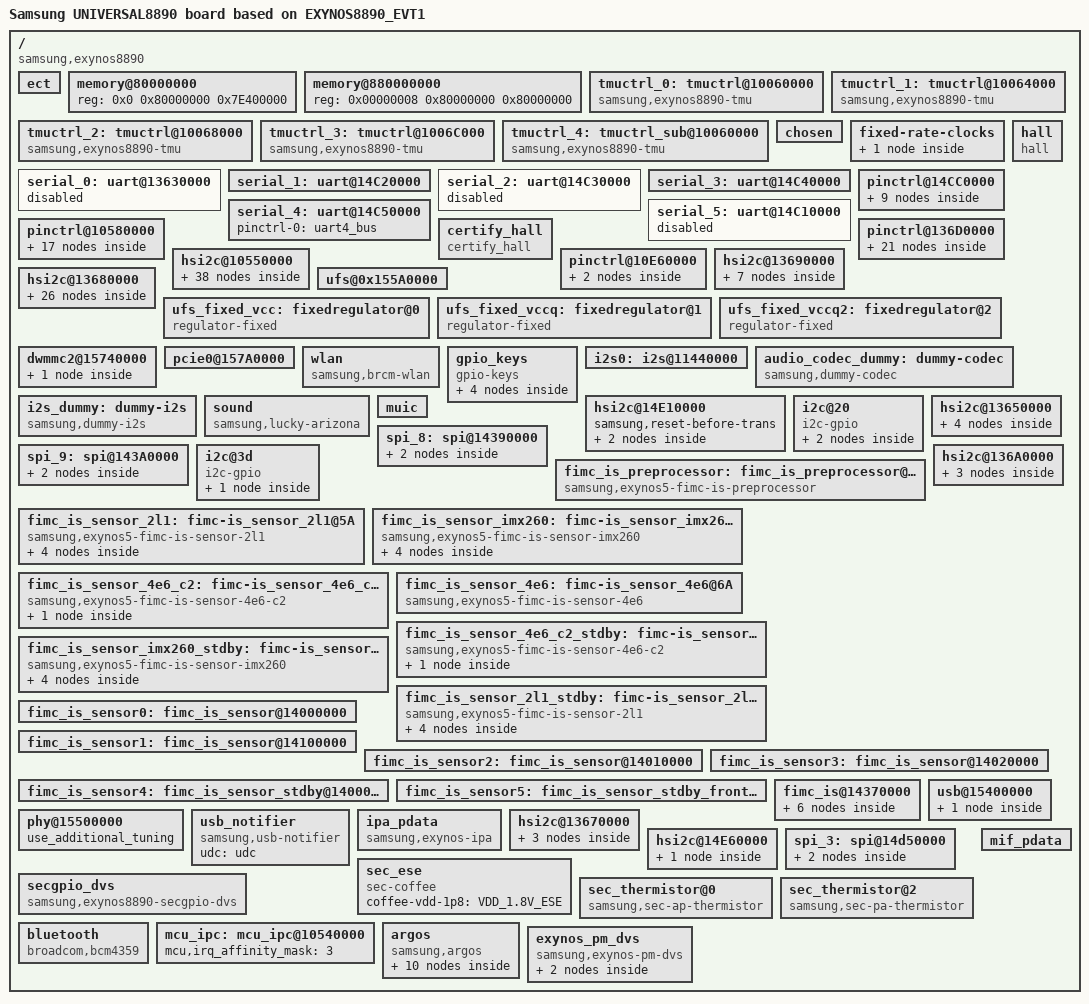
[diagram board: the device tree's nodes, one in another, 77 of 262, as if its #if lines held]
/*
 * SAMSUNG UNIVERSAL8890 board device tree source
 *
 * Copyright (c) 2013 Samsung Electronics Co., Ltd.
 *		http://www.samsung.com
 *
 * This program is free software; you can redistribute it and/or modify
 * it under the terms of the GNU General Public License version 2 as
 * published by the Free Software Foundation.
*/

#include "exynos8890.dtsi"
#include "exynos8890-rmem.dtsi"
#include "modem-ss335ap-pdata.dtsi"
#include "exynos8890-display-lcd.dtsi"

/ {
	model = "Samsung UNIVERSAL8890 board based on EXYNOS8890_EVT1";
	compatible = "samsung,exynos8890", "samsung,UNIVERSAL8890";

	ect {
		parameter_address = <0xA0000000>;
		parameter_size = <0x19000>;
	};

	memory@80000000 {
		device_type = "memory";
		reg = <0x0 0x80000000 0x7E400000>;
	};

	memory@880000000 {
		device_type = "memory";
		reg = <0x00000008 0x80000000 0x80000000>;
	};

	tmuctrl_0: tmuctrl@10060000 {
		compatible = "samsung,exynos8890-tmu";
		reg = <0x0 0x10060000 0x200>;
		interrupts = <0 77 0>;
		sensor_type = <NORMAL_SENSOR>;
		max_trigger_level = <8>;
		non_hw_trigger_levels = <7>;

		/* Throttling Level */
		trigger_levels_0 = <76>;
		trigger_levels_1 = <81>;
		trigger_levels_2 = <86>;
		trigger_levels_3 = <91>;
		trigger_levels_4 = <96>;
		trigger_levels_5 = <101>;
		trigger_levels_6 = <106>;
		trigger_levels_7 = <115>;

		trigger_enable_0 = <ENABLE>;
		trigger_enable_1 = <ENABLE>;
		trigger_enable_2 = <ENABLE>;
		trigger_enable_3 = <ENABLE>;
		trigger_enable_4 = <ENABLE>;
		trigger_enable_5 = <ENABLE>;
		trigger_enable_6 = <ENABLE>;
		trigger_enable_7 = <ENABLE>;

		trigger_type_0 = <THROTTLE_ACTIVE>;
		trigger_type_1 = <THROTTLE_ACTIVE>;
		trigger_type_2 = <THROTTLE_ACTIVE>;
		trigger_type_3 = <THROTTLE_ACTIVE>;
		trigger_type_4 = <THROTTLE_ACTIVE>;
		trigger_type_5 = <THROTTLE_ACTIVE>;
		trigger_type_6 = <THROTTLE_ACTIVE>;
		trigger_type_7 = <HW_TRIP>;

		freq_tab_count = <3>;

		freq_clip_max_0 = <1872000>;
		freq_clip_max_1 = <1352000>;
		freq_clip_max_2 = <728000>;

		cooling_level_0 = <76>;
		cooling_level_1 = <81>;
		cooling_level_2 = <86>;

		hotplug_enable = <1>;
		hotplug_in_threshold = <93>;
		hotplug_out_threshold = <96>;
	};

	tmuctrl_1: tmuctrl@10064000 {
		compatible = "samsung,exynos8890-tmu";
		reg = <0x0 0x10064000 0x200>;
		interrupts = <0 75 0>;
		sensor_type = <NORMAL_SENSOR>;
		max_trigger_level = <8>;
		non_hw_trigger_levels = <7>;

		/* Throttling Level */
		trigger_levels_0 = <76>;
		trigger_levels_1 = <81>;
		trigger_levels_2 = <86>;
		trigger_levels_3 = <91>;
		trigger_levels_4 = <96>;
		trigger_levels_5 = <101>;
		trigger_levels_6 = <106>;
		trigger_levels_7 = <115>;

		trigger_enable_0 = <ENABLE>;
		trigger_enable_1 = <ENABLE>;
		trigger_enable_2 = <ENABLE>;
		trigger_enable_3 = <ENABLE>;
		trigger_enable_4 = <ENABLE>;
		trigger_enable_5 = <ENABLE>;
		trigger_enable_6 = <ENABLE>;
		trigger_enable_7 = <ENABLE>;

		trigger_type_0 = <THROTTLE_ACTIVE>;
		trigger_type_1 = <THROTTLE_ACTIVE>;
		trigger_type_2 = <THROTTLE_ACTIVE>;
		trigger_type_3 = <THROTTLE_ACTIVE>;
		trigger_type_4 = <THROTTLE_ACTIVE>;
		trigger_type_5 = <THROTTLE_ACTIVE>;
		trigger_type_6 = <THROTTLE_ACTIVE>;
		trigger_type_7 = <HW_TRIP>;

		freq_tab_count = <5>;

		freq_clip_max_0 = <1482000>;
		freq_clip_max_1 = <1378000>;
		freq_clip_max_2 = <1170000>;
		freq_clip_max_3 = <1066000>;
		freq_clip_max_4 = <442000>;

		cooling_level_0 = <76>;
		cooling_level_1 = <81>;
		cooling_level_2 = <86>;
		cooling_level_3 = <91>;
		cooling_level_4 = <96>;
	};

	tmuctrl_2: tmuctrl@10068000 {
		compatible = "samsung,exynos8890-tmu";
		reg = <0x0 0x10068000 0x200>;
		interrupts = <0 78 0>;
		sensor_type = <NORMAL_SENSOR>;
		max_trigger_level = <8>;
		non_hw_trigger_levels = <7>;

		/* Throttling Level */
		trigger_levels_0 = <66>;
		trigger_levels_1 = <71>;
		trigger_levels_2 = <76>;
		trigger_levels_3 = <81>;
		trigger_levels_4 = <86>;
		trigger_levels_5 = <91>;
		trigger_levels_6 = <96>;
		trigger_levels_7 = <115>;

		trigger_enable_0 = <ENABLE>;
		trigger_enable_1 = <ENABLE>;
		trigger_enable_2 = <ENABLE>;
		trigger_enable_3 = <ENABLE>;
		trigger_enable_4 = <ENABLE>;
		trigger_enable_5 = <ENABLE>;
		trigger_enable_6 = <ENABLE>;
		trigger_enable_7 = <ENABLE>;

		trigger_type_0 = <THROTTLE_ACTIVE>;
		trigger_type_1 = <THROTTLE_ACTIVE>;
		trigger_type_2 = <THROTTLE_ACTIVE>;
		trigger_type_3 = <THROTTLE_ACTIVE>;
		trigger_type_4 = <THROTTLE_ACTIVE>;
		trigger_type_5 = <THROTTLE_ACTIVE>;
		trigger_type_6 = <THROTTLE_ACTIVE>;
		trigger_type_7 = <HW_TRIP>;

		freq_tab_count = <6>;

		freq_clip_max_0 = <600000>;
		freq_clip_max_1 = <600000>;
		freq_clip_max_2 = <546000>;
		freq_clip_max_3 = <419000>;
		freq_clip_max_4 = <260000>;
		freq_clip_max_5 = <260000>;

		cooling_level_0 = <76>;
		cooling_level_1 = <81>;
		cooling_level_2 = <86>;
		cooling_level_3 = <91>;
		cooling_level_4 = <96>;
		cooling_level_5 = <101>;

		/* gpu cooling related table */
		/* flags, driver_data(index), frequency */
		gpu_idx_num = <7>;
		gpu_cooling_table = < 0 0 650000
		                      0 1 600000
		                      0 2 546000
		                      0 3 419000
		                      0 4 338000
		                      0 5 260000
		                      0 6 TABLE_END>;
	};

	tmuctrl_3: tmuctrl@1006C000 {
		compatible = "samsung,exynos8890-tmu";
		reg = <0x0 0x1006C000 0x200>;
		interrupts = <0 76 0>;
		sensor_type = <NORMAL_SENSOR>;
		max_trigger_level = <4>;
		non_hw_trigger_levels = <4>;

		/* Throttling Level */
		trigger_levels_0 = <96>;
		trigger_levels_1 = <101>;
		trigger_levels_2 = <106>;
		trigger_levels_3 = <110>;

		trigger_enable_0 = <ENABLE>;
		trigger_enable_1 = <ENABLE>;
		trigger_enable_2 = <ENABLE>;
		trigger_enable_3 = <ENABLE>;

		trigger_type_0 = <THROTTLE_ACTIVE>;
		trigger_type_1 = <THROTTLE_ACTIVE>;
		trigger_type_2 = <THROTTLE_ACTIVE>;
		trigger_type_3 = <THROTTLE_ACTIVE>;

		freq_tab_count = <3>;

		freq_clip_max_0 = <60>;
		freq_clip_max_1 = <15>;
		freq_clip_max_2 = <5>;

		cooling_level_0 = <96>;
		cooling_level_1 = <101>;
		cooling_level_2 = <106>;

		/* isp cooling related table */
		/* flags, driver_data(index), frequency */
		isp_idx_num = <7>;
		isp_cooling_table = < 0 0 63
				      0 1 62
				      0 2 61
				      0 3 60
				      0 4 15
				      0 5  5
				      0 6 TABLE_END>;
	};

	tmuctrl_4: tmuctrl_sub@10060000 {
		compatible = "samsung,exynos8890-tmu";
		reg = <0x0 0x10060000 0x200>;
		interrupts = <0 77 0>;
		sensor_type = <VIRTUAL_SENSOR>;
		real_tmuctrl_id = <0>;
		max_trigger_level = <8>;
		non_hw_trigger_levels = <7>;

		/* Throttling Level */
		trigger_levels_0 = <76>;
		trigger_levels_1 = <81>;
		trigger_levels_2 = <86>;
		trigger_levels_3 = <91>;
		trigger_levels_4 = <96>;
		trigger_levels_5 = <101>;
		trigger_levels_6 = <106>;
		trigger_levels_7 = <115>;

		trigger_enable_0 = <ENABLE>;
		trigger_enable_1 = <ENABLE>;
		trigger_enable_2 = <ENABLE>;
		trigger_enable_3 = <ENABLE>;
		trigger_enable_4 = <ENABLE>;
		trigger_enable_5 = <ENABLE>;
		trigger_enable_6 = <ENABLE>;
		trigger_enable_7 = <ENABLE>;

		trigger_type_0 = <THROTTLE_ACTIVE>;
		trigger_type_1 = <THROTTLE_ACTIVE>;
		trigger_type_2 = <THROTTLE_ACTIVE>;
		trigger_type_3 = <THROTTLE_ACTIVE>;
		trigger_type_4 = <THROTTLE_ACTIVE>;
		trigger_type_5 = <THROTTLE_ACTIVE>;
		trigger_type_6 = <THROTTLE_ACTIVE>;
		trigger_type_7 = <HW_TRIP>;

		freq_tab_count = <3>;

		freq_clip_max_0 = <1872000>;
		freq_clip_max_1 = <1352000>;
		freq_clip_max_2 = <728000>;

		cooling_level_0 = <76>;
		cooling_level_1 = <81>;
		cooling_level_2 = <86>;

		hotplug_enable = <1>;
		hotplug_in_threshold = <93>;
		hotplug_out_threshold = <96>;
	};

	chosen {
		bootargs = "console=ttySAC4,115200 clk_ignore_unused ess_setup=0x86000000 androidboot.hardware=samsungexynos8890 ess_setup=0x86000000 pmic_info=3 androidboot.debug_level=0x4948 kpti=yes";
		linux,initrd-start = <0x82000000>;
		linux,initrd-end = <0x820FFFFF>;
	};

	fixed-rate-clocks {
		oscclk {
			compatible = "samsung,exynos8890-oscclk";
			clock-frequency = <26000000>;
		};
	};

	serial_0: uart@13630000 {
		status = "disabled";
	};

	serial_1: uart@14C20000 {
		status = "okay";
	};

	serial_2: uart@14C30000 {
		status = "disabled";
	};

	serial_3: uart@14C40000 {
		status = "okay";
	};

	pinctrl@14CC0000 {
		uart4_bus: uart4-bus {
			samsung,pins = "gpe1-1", "gpe1-0";
			samsung,pin-function = <2>;
			samsung,pin-pud = <0>;
		};
	};

	serial_4: uart@14C50000 {
		/* Enable UART channel for debug port */
		pinctrl-names = "default";
		pinctrl-0 = <&uart4_bus>;
		status = "okay";
	};

	serial_5: uart@14C10000 {
		status = "disabled";
	};

	pinctrl@10580000 {
		hall_irq_nopull: hall-irq-nopull {
			samsung,pins = "gpa0-1";
			samsung,pin-function = <0xf>;
			samsung,pin-pud = <0>;
			samsung,pin-drv = <0>;
		};

		hall_irq_pulldown: hall-irq-pulldown {
			samsung,pins = "gpa0-1";
			samsung,pin-function = <0xf>;
			samsung,pin-pud = <1>;
			samsung,pin-drv = <0>;
		};

		certify_hall_irq: certify-hall-irq {
			samsung,pins = "gpa0-2";
			samsung,pin-function = <0xf>;
			samsung,pin-pud = <0>;
			samsung,pin-drv = <0>;
		};

		pmic_irq: pmic-irq {
			samsung,pins = "gpa3-6";
			samsung,pin-pud = <3>;
			samsung,pin-drv = <3>;
		};

		chg_irq: chg-irq {
			samsung,pins = "gpa1-6";
			samsung,pin-function = <0xf>;
			samsung,pin-pud = <3>;
			samsung,pin-drv = <3>;
		};
	};

	hall {
		status = "okay";
		compatible = "hall";
		pinctrl-names = "hall-irq_nopull", "hall-irq_pulldown";
		pinctrl-0 = <&hall_irq_nopull>;
		pinctrl-1 = <&hall_irq_pulldown>;
		hall,gpio_flip_cover = <&gpa0 1 0>;
		sub_pcb_det,gpio_flip_cover = <&gpa3 0 0>;
	};

	certify_hall {
		status = "okay";
		compatible = "certify_hall";
		pinctrl-names = "default";
		pinctrl-0 = <&certify_hall_irq>;
		certify_hall,gpio_certify_cover = <&gpa0 2 0>;
	};

	pinctrl@136D0000 {
		/* Warm reset information from AP */
		pm_wrsti: pm-wrsti {
			samsung,pins = "gpd0-6";
			samsung,pin-con-pdn = <3>;
		};

		g3d_dvs: g3d-dvs {
			samsung,pins = "gpb2-0";
			samsung,pin-function = <0x2>;
		};

		smpl_warn: smpl-warn {
			samsung,pins = "gpb2-1";
			samsung,pin-function = <0>;
			samsung,pin-pud = <0>;
		};

		buck11en: buck11-en {
			samsung,pins = "gpi0-1";
			samsung,pin-pud = <0>;
		};
	};

	hsi2c@10550000{
		status = "okay";
		samsung,hs-mode;
		clock-frequency = <3000000>;
		samsung,hsi2c-batcher;
		samsung,use-apm;
		samsung,apm-always-clkon;
		s2mps16_pmic@66 {
			compatible = "samsung,s2mps16-pmic";
			reg = <0x66>;
			interrupts = <6 0 0>;
			interrupt-parent = <&gpa3>;
			pinctrl-names = "default";
			ten-bit-address;
			pinctrl-0 = <&pmic_irq &pm_wrsti &g3d_dvs &smpl_warn &buck11en>;
			gpios = <&gpb2 1 0>, <&gpb2 0 0x2>;
			smpl_warn_en = <1>; /* 1 : enable , 0 : disable*/
			/* range of smpl_warn_vth */
			/* 0x00 : 2.1V, 0x20 : 2.3V, 0x40 : 2.5V, 0x60 : 2.7V 0x80 : 2.9V */
			/* 0xA0 : 3.1V, 0xC0 : 3.3V, 0xE0 : 3.5V */
			smpl_warn_vth = <0x80>;
			/* LowBat_Hys[4:3] 00(100mV), 01(200mV), 10(300mV), 11(400mV) */
			smpl_warn_hys = <0x18>; /* LOwBat_Hys[4:3] 00(100mV)~11(400mV) */
			buck11_en;
			adc-on;
			buck_dvs_on;
			cache_data = <1>; /* 1 : enable , 0 : disable */
			g3d_en = <1>; /* 1 : enable , 0 : disable */
			dvs_en = <1>; /* 1 : enable , 0 : disable */
			ldo8_7_seq = <0x05>;
			ldo10_9_seq = <0x63>;
			/* RTC: wtsr/smpl */
			wtsr_en = <1>; /* enable */
			smpl_en = <1>; /* enable */
			wtsr_timer_val = <3>;	/* 1000ms */
			smpl_timer_val = <0>;	/* 100ms FIXME!!! */
			check_jigon = <0>; /* do not check jigon */
			/* RTC: If it's first boot, reset rtc to 1/1/2014 12:00:00(Wed) */
			init_time,sec = <0>;
			init_time,min = <0>;
			init_time,hour = <12>;
			init_time,mday = <1>;
			init_time,mon = <0>;
			init_time,year = <116>;
			init_time,wday = <5>;

			regulators {
				buck1_reg: BUCK1 {
					regulator-name = "vdd_mif";
					regulator-min-microvolt = <500000>;
					regulator-max-microvolt = <1000000>;
					regulator-always-on;
					regulator-ramp-delay = <12000>;
					regulator-initial-mode = <2>; /* controlled by PWREN_MIF */
				};

				buck2_reg: BUCK2 {
					regulator-name = "vdd_mngs";
					regulator-min-microvolt = <500000>;
					regulator-max-microvolt = <1300000>;
					regulator-always-on;
					regulator-ramp-delay = <12000>;
					regulator-initial-mode = <1>;
				};

				buck3_reg: BUCK3 {
					regulator-name = "vdd_apollo";
					regulator-min-microvolt = <500000>;
					regulator-max-microvolt = <1200000>;
					regulator-always-on;
					regulator-ramp-delay = <12000>;
					regulator-initial-mode = <1>;
				};

				buck4_reg: BUCK4 {
					regulator-name = "vdd_int";
					regulator-min-microvolt = <500000>;
					regulator-max-microvolt = <1000000>;
					regulator-always-on;
					regulator-ramp-delay = <12000>;
					regulator-initial-mode = <2>; /* controlled by PWREN_MIF */
				};

				buck5_reg: BUCK5 {
					regulator-name = "vdd_dispcam";
					regulator-min-microvolt = <500000>;
					regulator-max-microvolt = <1000000>;
					regulator-always-on;
					regulator-ramp-delay = <12000>;
					regulator-initial-mode = <2>; /* controlled by PWREN_MIF */
				};

				buck6_reg: BUCK6 {
					regulator-name = "vdd_g3d";
					regulator-min-microvolt = <500000>;
					regulator-max-microvolt = <1000000>;
					regulator-always-on;
					regulator-ramp-delay = <12000>;
					regulator-initial-mode = <1>;
				};

				buck7_reg: BUCK7 {
					regulator-name = "vdd_mem";
					regulator-min-microvolt = <900000>;
					regulator-max-microvolt = <1300000>;
					regulator-always-on;
					regulator-ramp-delay = <12000>;
					regulator-initial-mode = <3>;
				};

				buck8_reg: BUCK8 {
					regulator-name = "vdd_lldo";
					regulator-min-microvolt = <1000000>;
					regulator-max-microvolt = <1500000>;
					regulator-always-on;
					regulator-ramp-delay = <2000>;
					regulator-initial-mode = <3>;
				};

				buck9_reg: BUCK9 {
					regulator-name = "vdd_mldo";
					regulator-min-microvolt = <1800000>;
					regulator-max-microvolt = <2100000>;
					regulator-always-on;
					regulator-ramp-delay = <2700>;
					regulator-initial-mode = <3>;
				};

				buck11_reg: BUCK11 {
					regulator-name = "vdd_extra";
					regulator-min-microvolt = <700000>;
					regulator-max-microvolt = <1300000>;
					regulator-always-on;
					regulator-ramp-delay = <12000>;
					regulator-initial-mode = <1>;
				};

				ldo1_reg: LDO1 {
					regulator-name = "vdd_ldo1";
					regulator-min-microvolt = <500000>;
					regulator-max-microvolt = <900000>;
					regulator-ramp-delay = <12000>;
					regulator-initial-mode = <3>;
					regulator-always-on;
				};

				ldo2_reg: LDO2 {
					regulator-name = "vqmmc";
					regulator-min-microvolt = <1800000>;
					regulator-max-microvolt = <2800000>;
					regulator-ramp-delay = <12000>;
					regulator-initial-mode = <1>;
				};

				ldo3_reg: LDO3 {
					regulator-name = "vdd_ldo3";
					regulator-min-microvolt = <1620000>;
					regulator-max-microvolt = <1980000>;
					regulator-ramp-delay = <12000>;
					regulator-initial-mode = <3>;
					regulator-always-on;
				};

				ldo4_reg: LDO4 {
					regulator-name = "vdd_ldo4";
					regulator-min-microvolt = <800000>;
					regulator-max-microvolt = <1110000>;
					regulator-ramp-delay = <12000>;
					regulator-initial-mode = <1>;
					regulator-always-on;
				};

				ldo5_reg: LDO5 {
					regulator-name = "vdd_ldo5";
					regulator-min-microvolt = <1625000>;
					regulator-max-microvolt = <1975000>;
					regulator-ramp-delay = <12000>;
					regulator-always-on;
					regulator-initial-mode = <1>;
				};

				ldo6_reg: LDO6 {
					regulator-name = "vdd_ldo6";
					regulator-min-microvolt = <2250000>;
					regulator-max-microvolt = <3300000>;
					regulator-ramp-delay = <12000>;
					regulator-always-on;
					regulator-initial-mode = <1>;
				};

				ldo7_reg: LDO7 {
					regulator-name = "vdd_ldo7";
					regulator-min-microvolt = <700000>;
					regulator-max-microvolt = <1250000>;
					regulator-ramp-delay = <12000>;
					regulator-always-on;
					regulator-initial-mode = <1>;
				};

				ldo8_reg: LDO8 {
					regulator-name = "vdd_ldo8";
					regulator-min-microvolt = <700000>;
					regulator-max-microvolt = <1000000>;
					regulator-ramp-delay = <12000>;
					regulator-always-on;
					regulator-initial-mode = <1>;
				};

				ldo9_reg: LDO9 {
					regulator-name = "vdd_ldo9";
					regulator-min-microvolt = <700000>;
					regulator-max-microvolt = <1000000>;
					regulator-ramp-delay = <12000>;
					regulator-always-on;
					regulator-initial-mode = <1>;
				};

				ldo10_reg: LDO10 {
					regulator-name = "vdd_ldo10";
					regulator-min-microvolt = <700000>;
					regulator-max-microvolt = <1200000>;
					regulator-ramp-delay = <12000>;
					regulator-always-on;
					regulator-initial-mode = <1>;
				};

				ldo11_reg: LDO11 {
					regulator-name = "vdd_ldo11";
					regulator-min-microvolt = <700000>;
					regulator-max-microvolt = <1000000>;
					regulator-ramp-delay = <12000>;
					regulator-always-on;
					regulator-initial-mode = <1>;
				};

				ldo12_reg: LDO12 {
					regulator-name = "vdd_ldo12";
					regulator-min-microvolt = <1000000>;
					regulator-max-microvolt = <1300000>;
					regulator-ramp-delay = <12000>;
					regulator-always-on;
					regulator-initial-mode = <1>;
				};

				ldo13_reg: LDO13 {
					regulator-name = "vdd_ldo13";
					regulator-min-microvolt = <1000000>;
					regulator-max-microvolt = <1300000>;
					regulator-ramp-delay = <12000>;
					regulator-always-on;
					regulator-initial-mode = <1>;
				};

				ldo25_reg: LDO25 {
					regulator-name = "vdd_ldo25";
					regulator-min-microvolt = <700000>;
					regulator-max-microvolt = <1000000>;
					regulator-ramp-delay = <12000>;
					regulator-boot-on;
					regulator-always-on;
					regulator-initial-mode = <1>;
				};

				ldo26_reg: LDO26 {
					regulator-name = "vdd_ldo26";
					regulator-min-microvolt = <1000000>;
					regulator-max-microvolt = <1200000>;
					regulator-ramp-delay = <12000>;
				};

				ldo27_reg: LDO27 {
					regulator-name = "vdd_ldo27";
					regulator-min-microvolt = <1200000>;
					regulator-max-microvolt = <1200000>;
					regulator-ramp-delay = <12000>;
					regulator-boot-on;
					regulator-always-on;
					regulator-initial-mode = <1>;
				};

				ldo28_reg: LDO28 {
					regulator-name = "vdd_ldo28";
					regulator-min-microvolt = <2800000>;
					regulator-max-microvolt = <2800000>;
					regulator-always-on;
					regulator-boot-on;
					regulator-initial-mode = <3>;
				};

				ldo29_reg: LDO29 {
					regulator-name = "vdd_ldo29";
					regulator-min-microvolt = <3300000>;
					regulator-max-microvolt = <3300000>;
				};

				ldo30_reg: LDO30 {
					regulator-name = "VDD_1.8V_CODEC_PMIC";
					regulator-min-microvolt = <1800000>;
					regulator-max-microvolt = <1800000>;
					regulator-boot-on;
					regulator-always-on;
					regulator-initial-mode = <3>;
				};

				ldo31_reg: LDO31 {
					regulator-name = "VDD_1.2V_CODEC";
					regulator-min-microvolt = <1200000>;
					regulator-max-microvolt = <1200000>;
				};

				ldo32_reg: LDO32 {
					regulator-name = "HRM_1.8V_AP";
					regulator-min-microvolt = <1800000>;
					regulator-max-microvolt = <1800000>;
				};

				ldo33_reg: LDO33 {
					regulator-name = "HRM_3.3V_AP";
					regulator-min-microvolt = <3300000>;
					regulator-max-microvolt = <3300000>;
				};

				ldo34_reg: LDO34 {
					regulator-name = "VDD_MOT_3.3V";
					regulator-min-microvolt = <3300000>;
					regulator-max-microvolt = <3300000>;
				};

				ldo35_reg: LDO35 {
					regulator-name = "MST_LEVEL_3.0V";
					regulator-min-microvolt = <3000000>;
					regulator-max-microvolt = <3000000>;
				};

				ldo36_reg: LDO36 {
					regulator-name = "VDD_1.8V_ESE";
					regulator-min-microvolt = <1800000>;
					regulator-max-microvolt = <1800000>;
				};

				ldo37_reg: LDO37 {
					regulator-name = "VDD_NFC_1P8";
					regulator-min-microvolt = <1800000>;
					regulator-max-microvolt = <1800000>;
				};
			};
		};
	};

	pinctrl@10E60000 {
		sub_pmic_irq: sub-pmic-irq {
			samsung,pins = "gpi2-6";
			samsung,pin-function = <0>;
			samsung,pin-pud = <0>;
			samsung,pin-drv = <0>;
		};
	};


	hsi2c@13680000 {
		status = "okay";
		s2mpb02_pmic@59 {
			compatible = "s2mpb02,s2mpb02mfd";
			reg = <0x59>;

			s2mpb02,wakeup;
			pinctrl-names = "default";
			pinctrl-0 = <&sub_pmic_irq>;

			regulators {
				_buck1_reg: s2mpb02-buck1 {
					regulator-name = "VDD_1P3_EXT";
					regulator-min-microvolt = <1300000>;
					regulator-max-microvolt = <1300000>;
					regulator-always-on;
					regulator-boot-on;
				};

				_buck2_reg: s2mpb02-buck2 {
					regulator-name = "VDDD_CORE_0.8V_COMP";
					regulator-min-microvolt = <650000>;
					regulator-max-microvolt = <850000>;
				};

				_buckboost_reg: s2mpb02-bb {
					regulator-min-microvolt = <2600000>;
					regulator-max-microvolt = <4000000>;
					regulator-always-on;
					regulator-boot-on;
				};

				_ldo1_reg: s2mpb02-ldo1 {
					regulator-name = "VDDD_NORET_0.9V_COMP";
					regulator-min-microvolt = <950000>;
					regulator-max-microvolt = <950000>;
				};

				_ldo2_reg: s2mpb02-ldo2 {
					regulator-name = "VDDD_CORE_1.0V_COMP";
					regulator-min-microvolt = <1000000>;
					regulator-max-microvolt = <1000000>;
				};

				_ldo3_reg: s2mpb02-ldo3 {
					regulator-name = "VDDD_1.2V_CAM";
					regulator-min-microvolt = <1000000>;
					regulator-max-microvolt = <1200000>;
				};

				_ldo4_reg: s2mpb02-ldo4 {
					regulator-name = "VDDD_RET_1.0V_COMP";
					regulator-min-microvolt = <700000>;
					regulator-max-microvolt = <1050000>;
				};

				_ldo5_reg: s2mpb02-ldo5 {
					regulator-name = "VDDD_1.2V_VT";
					regulator-min-microvolt = <1200000>;
					regulator-max-microvolt = <1200000>;
				};

				_ldo6_reg: s2mpb02-ldo6 {
					regulator-name = "VDDIO_1.8V_VT";
					regulator-min-microvolt = <1800000>;
					regulator-max-microvolt = <1800000>;
				};

				_ldo7_reg: s2mpb02-ldo7 {
					regulator-name = "VDDIO_1.8V_CAM";
					regulator-min-microvolt = <1800000>;
					regulator-max-microvolt = <1800000>;
				};

				_ldo8_reg: s2mpb02-ldo8 {
					regulator-name = "VDDIO_1.8V_COMP";
					regulator-min-microvolt = <1800000>;
					regulator-max-microvolt = <1800000>;
				};

				_ldo9_reg: s2mpb02-ldo9 {
					regulator-name = "VDDA_1.8V_COMP";
					regulator-min-microvolt = <1800000>;
					regulator-max-microvolt = <1800000>;
				};

				_ldo10_reg: s2mpb02-ldo10 {
					regulator-name = "VDDA_1.8V_CAM";
					regulator-min-microvolt = <1875000>;
					regulator-max-microvolt = <1875000>;
				};

				_ldo11_reg: s2mpb02-ldo11 {
					regulator-name = "VDDA_2.9V_CAM";
					regulator-min-microvolt = <1000000>;
					regulator-max-microvolt = <2950000>;
				};

				_ldo12_reg: s2mpb02-ldo12 {
					regulator-name = "VDDAF_2.8V_CAM";
					regulator-min-microvolt = <2800000>;
					regulator-max-microvolt = <2800000>;
				};

				_ldo13_reg: s2mpb02-ldo13 {
					regulator-name = "VDDA_2.9V_VT";
					regulator-min-microvolt = <2900000>;
					regulator-max-microvolt = <2900000>;
				};

				_ldo14_reg: s2mpb02-ldo14 {
					regulator-name = "OIS_VM_2.8V";
					regulator-min-microvolt = <2800000>;
					regulator-max-microvolt = <2800000>;
				};

				_ldo15_reg: s2mpb02-ldo15 {
					regulator-name = "OIS_VDD_2.8V";
					regulator-min-microvolt = <2800000>;
					regulator-max-microvolt = <2800000>;
				};

				_ldo16_reg: s2mpb02-ldo16 {
					regulator-name = "TOUCH_VDD_3.3V";
					regulator-min-microvolt = <3300000>;
					regulator-max-microvolt = <3300000>;
					regulator-boot-on;
				};

				_ldo17_reg: s2mpb02-ldo17 {
					regulator-name = "OIS_VDD_1.8V";
					regulator-min-microvolt = <1800000>;
					regulator-max-microvolt = <1800000>;
				};

				_ldo18_reg: s2mpb02-ldo18 {
					regulator-name = "vmmc";
					regulator-min-microvolt = <2800000>;
					regulator-max-microvolt = <2800000>;
				};
			};

			torch {
				torch1-gpio = "gpc0-3";
				flash1-gpio = "gpc0-2";

				status = "okay";

				leds1 {
					ledname = "leds-sec1";
					/* S2MPB02_FLASH_LED_1 */
					id = <0>;
					/* S2MPB02_FLASH_CURRENT */
					brightness = <0xA>;
					/* S2MPB02_FLASH_TIMEOUT */
					timeout = <0x7>;
				};

				leds2 {
					ledname = "torch-sec1";
					/* S2MPB02_TORCH_LED_1 */
					id = <1>;
					/* S2MPB02_TORCH_CURRENT */
					brightness = <0x9>;
					/* S2MPB02_TORCH_TIMEOUT */
					timeout = <0xF>;
				};
			};
		};
	};

	hsi2c@13690000 {
		status = "okay";

		max77838@60 {
			compatible = "maxim,max77838";
			/* UVLO_CFG[1:0]  00(2.3V), 01(2.35V), 10(2.4V), 11(2.45V) */
			uvlo-fall-threshold = <0>;
			reg = <0x60>;

			regulators {
				ldo1: LDO1 {
					regulator-name = "vdd_1p8_ddi";
					regulator-min-microvolt = <1800000>;
					regulator-max-microvolt = <1800000>;
					regulator-boot-on;
				};

				ldo2: LDO2 {
					regulator-name = "tsp_io";
					regulator-min-microvolt = <1850000>;
					regulator-max-microvolt = <1850000>;
				};

				ldo3: LDO3 {
					regulator-name = "vdd_3p0_ddi";
					regulator-min-microvolt = <3000000>;
					regulator-max-microvolt = <3000000>;
					regulator-boot-on;
				};

				ldo4: LDO4 {
					regulator-name = "tsp_avdd";
					regulator-min-microvolt = <3300000>;
					regulator-max-microvolt = <3300000>;
				};

				buck: BUCK {
					regulator-name = "vdd_1p6_ddr";
					regulator-min-microvolt = <1600000>;
					regulator-max-microvolt = <1600000>;
					regulator-boot-on;
				};
			};
		};
	};

	ufs@0x155A0000 {
		status = "okay";
		ufs,pmd-attr-mode = "FAST";
		ufs,pmd-attr-lane = /bits/ 8 <1>;
		ufs,pmd-attr-gear = /bits/ 8 <3>;
		ufs,pmd-attr-hs-series = "HS_rate_b";
		ufs-opts-skip-connection-estab;
		ufs-opts-use-seperated-pclk;
		ufs-rx-adv-fine-gran-sup_en = <0>;
		ufs-rx-min-activate-time-cap = <3>;
		ufs-rx-hibern8-time-cap = <2>;
		ufs-tx-hibern8-time-cap = <2>;
		ufs-wait-cdr-lock = <0x6e>;

		vcc-supply = <&ufs_fixed_vcc>;
		vccq-supply = <&ufs_fixed_vccq>;
		vccq2-supply = <&ufs_fixed_vccq2>;
		vcc-fixed-regulator;
		vccq-fixed-regulator;
		vccq2-fixed-regulator;

		ufs-cap-clk-gating;
		ufs-cap-hibern8-with-clk-gating;

		phy-init =
			<PA_DBG_OPTION_SUITE 0x2e030103 PMD_ALL UNIPRO_DBG_MIB>,
			<0x155E 0x0 PMD_ALL UNIPRO_STD_MIB>,
			<0x00f 0xfa PMD_ALL PHY_PMA_COMN>,
			<0x010 0x82 PMD_ALL PHY_PMA_COMN>,
			<0x011 0x1e PMD_ALL PHY_PMA_COMN>,
			<0x012 0x80 PMD_ALL PHY_PMA_COMN>,
			<0x017 0x94 PMD_ALL PHY_PMA_COMN>,
			<0x034 0x31 PMD_ALL PHY_PMA_TRSV>,
			<0x035 0x40 PMD_ALL PHY_PMA_TRSV>,
			<0x038 0x3f PMD_ALL PHY_PMA_TRSV>,
			<0x049 0x00 PMD_ALL PHY_PMA_TRSV>,
			<0x04a 0x10 PMD_ALL PHY_PMA_TRSV>,
			<0x04c 0x5b PMD_ALL PHY_PMA_TRSV>,
			<0x05c 0x14 PMD_ALL PHY_PMA_TRSV>,
			<PA_DBG_OV_TM true PMD_ALL PHY_PCS_COMN>,
			<0x401 0x09 PMD_ALL PHY_PCS_COMN>,
			<0x27a 0x10 PMD_ALL PHY_PCS_RXTX>,
			<0x30e 0x01 PMD_ALL PHY_PCS_RXTX>,
			<0x31f 0x04 PMD_ALL PHY_PCS_RXTX>,
			<0x32c 0x00 PMD_ALL PHY_PCS_RXTX>,
			<PA_DBG_OV_TM false PMD_ALL PHY_PCS_COMN>,
			<0 0 0 0>;

		post-phy-init =
			<PA_DBG_MODE 0x1 PMD_ALL UNIPRO_DBG_MIB>,
			<PA_SAVECONFIGTIME 0x7d0 PMD_ALL UNIPRO_STD_MIB>,
			<PA_DBG_MODE 0x0 PMD_ALL UNIPRO_DBG_MIB>,
			<0 0 0 0>;

		calib-of-pwm =
			<PA_DBG_OV_TM true PMD_ALL PHY_PCS_COMN>,
			<0x337 0x21 PMD_PWM PHY_PCS_RXTX>,
			<PA_DBG_OV_TM false PMD_ALL PHY_PCS_COMN>,
			<0 0 0 0>;

		calib-of-hs-rate-a =
			<0x034 0x32 PMD_HS_G3_L1 PHY_PMA_TRSV>,
			<0x035 0x40 (PMD_HS_G1_L1 | PMD_HS_G2_L1) PHY_PMA_TRSV>,
			<0x035 0x42 PMD_HS_G3_L1 PHY_PMA_TRSV>,
			<0x037 0x43 PMD_HS_G3_L1 PHY_PMA_TRSV>,
			<0x41a 0x01 PMD_HS_G3_L1 PHY_PCS_COMN>,
			<0 0 0 0>;

		calib-of-hs-rate-b =
			<0x034 0x32 PMD_HS_G3_L1 PHY_PMA_TRSV>,
			<0x035 0x40 (PMD_HS_G1_L1 | PMD_HS_G2_L1) PHY_PMA_TRSV>,
			<0x035 0x42 PMD_HS_G3_L1 PHY_PMA_TRSV>,
			<0x037 0x43 PMD_HS_G3_L1 PHY_PMA_TRSV>,
			<0x41a 0x01 PMD_HS_G3_L1 PHY_PCS_COMN>,
			<0 0 0 0>;

		post-calib-of-pwm =
			<0x015 0x00 PMD_PWM PHY_PMA_COMN>,
			<0x41a 0x00 PMD_PWM PHY_PCS_COMN>,
			<0 0 0 0>;

		post-calib-of-hs-rate-a =
			<0x049 0x02 (PMD_HS_G2_L1 | PMD_HS_G3_L1) PHY_PMA_TRSV>,
			<0x04a 0x37 (PMD_HS_G2_L1 | PMD_HS_G3_L1) PHY_PMA_TRSV>,
			<0 0 0 0>;

		post-calib-of-hs-rate-b =
			<0x049 0x02 (PMD_HS_G2_L1 | PMD_HS_G3_L1) PHY_PMA_TRSV>,
			<0x04a 0x37 (PMD_HS_G2_L1 | PMD_HS_G3_L1) PHY_PMA_TRSV>,
			<0 0 0 0>;

		pma-restore =
			<0x00f 0xfa PMD_ALL PHY_PMA_COMN>,
			<0x010 0x82 PMD_ALL PHY_PMA_COMN>,
			<0x011 0x1e PMD_ALL PHY_PMA_COMN>,
			<0x012 0x80 PMD_ALL PHY_PMA_COMN>,
			<0x017 0x94 PMD_ALL PHY_PMA_COMN>,
			<0x034 0x31 (PMD_PWM |(PMD_HS_G1_L1 | PMD_HS_G2_L1)) PHY_PMA_TRSV>,
			<0x034 0x32 PMD_HS_G3_L1 PHY_PMA_TRSV>,
			<0x035 0x40 PMD_PWM PHY_PMA_TRSV>,
			<0x035 0x40 (PMD_HS_G1_L1 | PMD_HS_G2_L1) PHY_PMA_TRSV>,
			<0x035 0x42 PMD_HS_G3_L1 PHY_PMA_TRSV>,
			<0x037 0x43 PMD_HS_G3_L1 PHY_PMA_TRSV>,
			<0x038 0x3f PMD_ALL PHY_PMA_TRSV>,
			<0x049 0x00 PMD_PWM PHY_PMA_TRSV>,
			<0x04a 0x10 PMD_PWM PHY_PMA_TRSV>,
			<0x049 0x02 PMD_HS PHY_PMA_TRSV>,
			<0x04a 0x37 PMD_HS PHY_PMA_TRSV>,
			<0x04c 0x5b PMD_HS PHY_PMA_TRSV>,
			<0x05c 0x14 PMD_HS PHY_PMA_TRSV>,
			<0 0 0 0>;
	};

	ufs_fixed_vcc: fixedregulator@0 {
		       compatible = "regulator-fixed";
		       regulator-name = "ufs-vcc";
		       gpio = <&gpg0 0 0>;
		       regulator-boot-on;
		       enable-active-high;
	};

	ufs_fixed_vccq: fixedregulator@1 {
			compatible = "regulator-fixed";
			regulator-name = "ufs-vccq";
			gpio = <&gpg0 0 0>;
			regulator-boot-on;
			enable-active-high;
	};

	ufs_fixed_vccq2: fixedregulator@2 {
			 compatible = "regulator-fixed";
			 regulator-name = "ufs-vccq2";
			 gpio = <&gpg0 0 0>;
			regulator-boot-on;
			 enable-active-high;
			 startup-delay-us = <2000>;
			 endup-delay-us = <2000>;
	};

	dwmmc2@15740000 {
		status = "okay";
		num-slots = <1>;
		supports-4bit;
		supports-cmd23;
		supports-erase;
		supports-highspeed;
		sd-uhs-sdr50;
		sd-uhs-sdr104;
		card-detect-gpio;
		bypass-smu;
		bypass-for-allpass;
		clock-gate;
		use-fine-tuning;
		card-init-hwacg-ctrl;
		samsung,voltage-int-extra = <0x7>;
		switch_transfer;
		ignore-phase = <(1 << 7)>;
		fifo-depth = <0x40>;
		qos_int_level = <255000>;
		samsung,dw-mshc-ciu-div = <3>;
		desc-size = <4>;
		card-detect-delay = <200>;
		data-timeout = <200>;
		hto-timeout = <80>;
		clock-frequency = <800000000>;
		samsung,dw-mshc-sdr-timing = <3 0 2 0>;
		samsung,dw-mshc-ddr-timing = <3 0 2 1>;

		samsung,dw-mshc-sdr50-timing = <3 0 2 0>;
		samsung,dw-mshc-sdr104-timing = <3 0 2 0>;

		num-ref-clks = <9>;
		ciu_clkin = <25 50 50 25 50 100 200 50 50>;

		/* Swapping clock drive strength */
		clk-drive-number = <4>;
		pinctrl-names = "default",
			"fast-slew-rate-1x",
			"fast-slew-rate-2x",
			"fast-slew-rate-3x",
			"fast-slew-rate-4x";
		pinctrl-0 = <&sd2_clk &sd2_cmd &sd2_bus1 &sd2_bus4 &dwmmc2_cd_ext_irq &tflash_en>;
		pinctrl-1 = <&sd2_clk_fast_slew_rate_1x>;
		pinctrl-2 = <&sd2_clk_fast_slew_rate_2x>;
		pinctrl-3 = <&sd2_clk_fast_slew_rate_3x>;
		pinctrl-4 = <&sd2_clk_fast_slew_rate_4x>;

		card-detect = <&gpa1 5 0xf>;
		sec-sd-slot-type = <2>;
		vmmc-gpio = <&gpa3 7 1>;
		slot@0 {
			reg = <0>;
			bus-width = <4>;
			disable-wp;
		};
	};

	pcie0@157A0000 {
		status = "okay";
	};

	wlan {
		compatible = "samsung,brcm-wlan";
		gpios = <&gpj1 3 0x1 /* WLAN_EN */
				 &gpa0 7 0x1 /* WLAN HOST WAKE GPIO_0 */>;
		pinctrl-names = "default";
		pinctrl-0 = <&cfg_wlanen &wlan_host_wake>;
		status = "okay";
	};

	pinctrl@10580000 {
		key_power: key-power {
			samsung,pins = "gpa2-4";
			samsung,pin-function = <0xf>;
			samsung,pin-pud = <0>;
			samsung,pin-drv = <0>;
		};

		key_voldown: key-voldown {
			samsung,pins = "gpa0-4";
			samsung,pin-function = <0xf>;
			samsung,pin-pud = <0>;
			samsung,pin-drv = <0>;
		};

		key_volup: key-volup {
			samsung,pins = "gpa0-3";
			samsung,pin-function = <0xf>;
			samsung,pin-pud = <0>;
			samsung,pin-drv = <0>;
		};

		key_home: key-home {
			samsung,pins = "gpa0-5";
			samsung,pin-function = <0xf>;
			samsung,pin-pud = <3>;
			samsung,pin-drv = <0>;
		};
	};

	gpio_keys {
		compatible = "gpio-keys";
		pinctrl-names = "default";
		pinctrl-0 = <&key_power &key_voldown &key_volup &key_home>;
		button@1 {
			label = "gpio-keys: KEY_POWER";
			interrupts = <4 0 0>;
			interrupt-parent = <&gpa2>;
			linux,code = <116>;
			gpios = <&gpa2 4 0xf>;
			gpio-key,wakeup = <1>;
		};
		button@2 {
			label = "gpio-keys: KEY_VOLUMEDOWN";
			interrupts = <4 0 0>;
			interrupt-parent = <&gpa0>;
			linux,code = <114>;
			gpios = <&gpa0 4 0xf>;
		};
		button@3 {
			label = "gpio-keys: KEY_VOLUMEUP";
			interrupts = <3 0 0>;
			interrupt-parent = <&gpa0>;
			linux,code = <115>;
			gpios = <&gpa0 3 0xf>;
		};
		button@4 {
			label = "gpio-keys: KEY_HOMEPAGE";
			interrupts = <5 0 0>;
			interrupt-parent = <&gpa0>;
			linux,code = <172>;
			gpios = <&gpa0 5 0xf>;
			gpio-key,wakeup = <1>;
		};
	};

	pinctrl@10580000 {
		attn_irq: attn-irq {
			samsung,pins = "gpa1-0";
			samsung,pin-function = <0xf>;
			samsung,pin-pud = <0>;
			samsung,pin-drv = <0>;
		};

		attn_input: attn-input {
			samsung,pins = "gpa1-0";
			samsung,pin-function = <0>;
			samsung,pin-pud = <1>;
		};
	};

	pinctrl@14CC0000 {
		/* touchkey i2c*/
		cfg_i2c: cfg-i2c {
			samsung,pins = "gpe5-3", "gpe5-2";
			samsung,pin-function = <0>;
			samsung,pin-pud = <0>;
			samsung,pin-drv = <0>;
		};
		cfg_gpio: cfg-gpio {
			samsung,pins = "gpe5-3", "gpe5-2";
			samsung,pin-function = <0>;
			samsung,pin-pud = <1>;
			samsung,pin-drv = <0>;
		};
	};

	pinctrl@10580000 {
		/* touchkey interrupt*/
		cfg_irq: cfg-irq {
			samsung,pins = "gpa0-0";
			samsung,pin-function = <0xf>;
			samsung,pin-pud = <0>;
			samsung,pin-drv = <0>;
		};
		cfg_input: cfg-input {
			samsung,pins = "gpa0-0";
			samsung,pin-function = <0>;
			samsung,pin-pud = <0>;
			samsung,pin-drv = <0>;
		};
		sub_det: sub-det {
			samsung,pins = "gpa3-0";
			samsung,pin-function = <0>;
			samsung,pin-pud = <0>;
			samsung,pin-drv = <0>;
		};
	};

	pinctrl@14CC0000 {
		tsp_id: tsp-id {
		samsung,pins = "gpe7-1";
		samsung,pin-function = <0x0>;
		samsung,pin-pud = <0>;
		samsung,pin-drv = <0>;
		};
	};

	i2s0: i2s@11440000 {
		samsung,supports-esa-dma;
		samsung,supports-sec-compr;
		status = "okay";
	};

	audio_codec_dummy: dummy-codec {
		compatible = "samsung,dummy-codec";
		status = "okay";
	};

	i2s_dummy: dummy-i2s {
		compatible = "samsung,dummy-i2s";
		status = "okay";
	};

	sound {
		compatible = "samsung,lucky-arizona";
		samsung,audio-cpu = <
			&i2s0			/* primary */
			&i2s_dummy
			&i2s_dummy
			&i2s0			/* secondary */
			&i2s_dummy		/* voice wakeup */
			&i2s_dummy		/* dsp trace */
			&eax			/* eax0 ~ 3 */
			&eax
			&eax
			&eax
			&i2s_dummy		/* dsm c2c */
			&i2s0			/* offload playback */
		>;
		samsung,audio-codec = <
			&audio_codec
			&audio_codec
			&audio_codec
			&audio_codec
			&audio_codec_dummy
			&audio_codec_dummy
			&audio_codec
			&audio_codec
			&audio_codec
			&audio_codec
			&audio_codec_dummy	/* dsm c2c */
			&audio_codec		/* offload playback */
		>;
		clocks = <&clock 1001>;
		clock-names = "mclk";
		status = "okay";
	};

	hsi2c@14E10000 {
		status = "okay";
		samsung,reset-before-trans;
		touchscreen@49 {
			compatible = "stm,fts_touch";
			reg = <0x49>;
			pinctrl-names = "on_state", "off_state";
			pinctrl-0 = <&attn_irq &tsp_id>;
			pinctrl-1 = <&attn_input>;
			stm,tspid2_gpio = <&gpe7 2 0>;
			stm,irq_gpio = <&gpa1 0 0>;
			stm,irq_type = <8200>;
			stm,num_lines = <28 16>;		/* rx tx */
			stm,max_coords = <4095 4095>;	/* x y */
			stm,grip_area = <512>;
			stm,regulator_dvdd = "tsp_io";
			stm,regulator_avdd = "tsp_avdd";
			stm,project_name = "HERO2", "G935";
			stm,support_gesture = <1>;
		};
	};

	hsi2c@14E10000 {
		status = "okay";
		touchscreen@48{
			compatible = "sec,sec_ts";
			reg = <0x48>;
			pinctrl-names = "on_state", "off_state";
			pinctrl-0 = <&attn_irq &tsp_id>;
			pinctrl-1 = <&attn_input>;
			sec,irq_gpio = <&gpa1 0 0>;
			sec,irq_type = <8200>;
			sec,num_lines = <28 16>;		/* rx tx */
			sec,max_coords = <4095 4095>;	/* x y */
			sec,grip_area = <512>;
			sec,regulator_dvdd = "tsp_io";
			sec,regulator_avdd = "tsp_avdd";
			sec,project_name = "HERO", "G930";
			sec,firmware_name = "tsp_sec/hero.bin";
		};
	};

	i2c@20{
		compatible = "i2c-gpio";
		gpios = < &gpe5 2 0 /* sda */
				&gpe5 3 0 /* scl */
				>;
		i2c-gpio,delay-us = <2>;
		#address-cells = <1>;
		#size-cells = <0>;
		status = "okay";
		pinctrl-names = "default","on_i2c","off_i2c";
		pinctrl-0 = <&hs_i2c3_bus &sub_det>;
		pinctrl-1 = <&cfg_i2c>;
		pinctrl-2 = <&cfg_gpio>;
		touchkey@20 {
			compatible = "abov,mc96ft16xx";
			pinctrl-names = "on_irq","off_irq";
			pinctrl-0 = <&cfg_irq>;
			pinctrl-1 = <&cfg_input>;
			reg = <0x20>;
			interrupts = <0 0 0>;
			interrupt-parent = <&gpa0>;
			abov,sda-gpio = <&gpe5 2 0>;
			abov,scl-gpio = <&gpe5 3 0>;
			abov,irq-gpio = <&gpa0 0 1>;
			abov,regulator_avdd = "TOUCH_VDD_3.3V";
			abov,fw_path = "abov/abov_hero.fw";
			abov,boot-on-ldo = "true";
		};

		touchkey@40 {
			compatible = "cypress,cypress_touchkey";
			pinctrl-names = "on_irq","off_irq";
			pinctrl-0 = <&cfg_irq>;
			pinctrl-1 = <&cfg_input>;
			reg = <0x40>;
			interrupts = <0 0 0>;
			interrupt-parent = <&gpa0>;
			cypress,sda-gpio = <&gpe5 2 0>;
			cypress,scl-gpio = <&gpe5 3 0>;
			cypress,irq-gpio = <&gpa0 0 1>;
			cypress,ap-io-power;
			cypress,i2c-gpio;
			cypress,ic-stabilizing-time = <150>;
			cypress,boot-on-ldo;
			cypress,one_keypad;
			cypress,sub-det = <&gpa3 0 0>;
			cypress,regulator_avdd = "TOUCH_VDD_3.3V";
			cypress,fw_path = "cypress/cy8cmbr3145_hero.fw";
		};
	};

	pinctrl@10580000 {
		max77854_irq: max77854-irq {
			samsung,pins = "gpa1-6";
			samsung,pin-function = <0xf>;
			samsung,pin-pud = <0>;
			samsung,pin-drv = <0>;
		};
	};

	hsi2c@13650000 {
		status = "okay";

		max77854@66 {
			compatible = "maxim,max77854";
			pinctrl-names = "default";
			pinctrl-0 = <&max77854_irq &pwm_tout1>;
			reg = <0x66>;
			max77854,irq-gpio = <&gpa1 6 1>;
			muic-universal,irq-gpio = <&gpa1 6 1>;
			muic-universal,chip_name = "max,max77854";
			max77854,wakeup;
			muic,undefined_range;

			regulators {
				ESAFEOUT1 {
					regulator-compatible = "safeout1";
					regulator-name = "safeout1_range";
					regulator-min-microvolt = <3300000>;
					regulator-max-microvolt = <4900000>;
					regulator-boot-on;
				};

				ESAFEOUT2 {
					regulator-compatible = "safeout2";
					regulator-name = "safeout2_range";
					regulator-min-microvolt = <3300000>;
					regulator-max-microvolt = <4900000>;
				};
			};
		};
	};

	muic {
		status = "okay";
		muic,support-list = "+OTG:GND",
				"-MHL:1K",
				"-VZW Accessory:28.7K",
				"-VZW Incompatible:34K",
				"+RDU TA:40.2K",
				"+HMT:49.9K",
				"-Audiodock:64.9K",
				"-USB LANHUB:80.07K",
				"-Charging Cable:102K",
				"+Game Pad:121K",
				"+TYPE1 Charger:200K",
				"+Jig USB Off:255K",
				"+Jig USB On:301K",
				"-Deskdock:365K",
				"-TYPE2 Charger:442K",
				"+Jig UART Off:523K",
				"+Jig UART On:619K",
				"+TA:OPEN",
				"+USB:OPEN",
				"+CDP:OPEN",
				"+Undefined Charging:XXX";
		muic,afcmode-tx = /bits/ 8 <0x46>;
		muic,qc-hv = /bits/ 8 <0x9>;
	};

	pinctrl@136D0000 {
		fimc_is_flash_host: fimc-is-flash-host {
			samsung,pins = "gpc0-2", "gpc0-3";
			samsung,pin-function = <1>;
			samsung,pin-pud = <1>;
			samsung,pin-drv = <0>;
		};

		fimc_is_flash_is: fimc-is-flash-is {
			samsung,pins = "gpc0-2", "gpc0-3";
			samsung,pin-function = <2>;
			samsung,pin-pud = <1>;
			samsung,pin-drv = <0>;
		};

		fimc_is_comp_int_out: fimc-is-comp-int-out {
			samsung,pins = "gpc0-0";
			samsung,pin-function = <1>;
			samsung,pin-pud = <0>;
			samsung,pin-drv = <0>;
			samsung,pin-val = <0>;
		};

		fimc_is_comp_int_fn: fimc-is-comp-int-fn {
			samsung,pins = "gpc0-0";
			samsung,pin-function = <0xf>;
			samsung,pin-pud = <0>;
			samsung,pin-drv = <0>;
		};

		fimc_is_spi_pin0: fimc-is-spi-pin0 {
			samsung,pins = "gpc3-3", "gpc3-2", "gpc3-0";
			samsung,pin-function = <2>;
			samsung,pin-pud = <1>;
			samsung,pin-drv = <3>;
		};

		fimc_is_spi_ssn0_inpd: fimc-is-spi-ssn0-inpd {
			samsung,pins = "gpc3-1";
			samsung,pin-function = <0>;
			samsung,pin-pud = <1>;
			samsung,pin-drv = <0>;
		};

		fimc_is_spi_ssn0_inpu: fimc-is-spi-ssn0-inpu {
			samsung,pins = "gpc3-1";
			samsung,pin-function = <0>;
			samsung,pin-pud = <3>;
			samsung,pin-drv = <0>;
		};

		fimc_is_spi_pin1: fimc-is-spi-pin1 {
			samsung,pins = "gpc3-7", "gpc3-6", "gpc3-4";
			samsung,pin-function = <2>;
			samsung,pin-pud = <1>;
			samsung,pin-drv = <3>;
		};

		fimc_is_ois_hsi2c_on: fimc-is-ois-hsi2c-on {
			samsung,pins = "gpd2-3", "gpd2-2";
			samsung,pin-function = <2>;
			samsung,pin-pud = <0>;
			samsung,pin-drv = <0>;
		};

		fimc_is_hsi2c_off: fimc-is-hsi2c-off {
			samsung,pins = "gpd2-3", "gpd2-2";
			samsung,pin-function = <0>;
			samsung,pin-pud = <0>;
			samsung,pin-drv = <3>;
		};

		fimc_is_i2c0_off: fimc_is_i2c0_off {
			samsung,pins = "gpc2-1", "gpc2-0";
			samsung,pin-function = <0>;
			samsung,pin-pud = <0>;
			samsung,pin-drv = <0>;
		};

		fimc_is_i2c0_host: fimc_is_i2c0_host {
			samsung,pins = "gpc2-1", "gpc2-0";
			samsung,pin-function = <0>;
			samsung,pin-pud = <0>;
			samsung,pin-drv = <0>;
		};

		fimc_is_i2c0_fw: fimc_is_i2c0_fw {
			samsung,pins = "gpc2-1", "gpc2-0";
			samsung,pin-function = <2>;
			samsung,pin-pud = <0>;
			samsung,pin-drv = <0>;
		};

		fimc_is_i2c2_off: fimc_is_i2c2_off {
			samsung,pins = "gpc2-5", "gpc2-4";
			samsung,pin-function = <0>;
			samsung,pin-pud = <0>;
			samsung,pin-drv = <0>;
		};

		fimc_is_i2c2_host: fimc_is_i2c2_host {
			samsung,pins = "gpc2-5", "gpc2-4";
			samsung,pin-function = <1>;
			samsung,pin-pud = <0>;
			samsung,pin-drv = <0>;
		};

		fimc_is_i2c2_fw: fimc_is_i2c2_fw {
			samsung,pins = "gpc2-5", "gpc2-4";
			samsung,pin-function = <2>;
			samsung,pin-pud = <0>;
			samsung,pin-drv = <0>;
		};
	};

	pinctrl@10580000 {
		ssp_host_req: ssp-host-req {
			samsung,pins = "gpa3-4";
			samsung,pin-function = <0xf>;
			samsung,pin-pud = <1>;
			samsung,pin-drv = <3>;
		};

		/*ssp_host_wake: ssp-host-wake {
			samsung,pins = "gpa3-1";
			samsung,pin-function = <0>;
			samsung,pin-pud = <3>;
			samsung,pin-drv = <3>;
		};*/

		/*ssp_host_wake_irq: ssp-host-wake-irq {
			samsung,pins = "gpa3-1";
			samsung,pin-function = <0xf>;
			samsung,pin-pud = <1>;
			samsung,pin-drv = <3>;
		};*/

		ssp_batch_wake_irq: ssp-batch-wake-irq {
			samsung,pins = "gpa3-1";
			samsung,pin-function = <0xf>;
			samsung,pin-pud = <1>;
			samsung,pin-drv = <3>;
		};
	};

	pinctrl@136D0000 {
		ssp_gps_pwr_en: ssp-gps-pwr-en {
			samsung,pins = "gpb1-1";
			samsung,pin-function = <1>;
			samsung,pin-pud = <0>;
			samsung,pin-drv = <3>;
		};
	};

	pinctrl@14CC0000 {
		spi1_mosi_sck_ssn: spi1-mosi-sck-ssn {
			samsung,pins = "gpe2-7", "gpe2-4", "gpe2-5";
			samsung,pin-function = <2>;
			samsung,pin-pud = <3>;
			samsung,pin-drv = <3>;
		};

		spi1_miso: spi1-miso {
			samsung,pins = "gpe2-6";
			samsung,pin-function = <2>;
			samsung,pin-pud = <1>;
			samsung,pin-drv = <3>;
		};

		ssp_mcu_req: ssp-mcu-req {
			samsung,pins = "gpe6-4";
			samsung,pin-function = <1>;
			samsung,pin-pud = <0>;
			samsung,pin-drv = <3>;
		};

		ssp_mcu_resp: ssp-mcu-resp {
			samsung,pins = "gpg0-2";
			samsung,pin-function = <0>;
			samsung,pin-pud = <3>;
			samsung,pin-drv = <3>;
		};
	};

	spi_8: spi@14390000 {
		#address-cells = <1>;
		#size-cells = <0>;
		pinctrl-names = "default", "spi_out", "spi_fn";
		pinctrl-0 = <&fimc_is_spi_pin0_out>;
		pinctrl-1 = <&fimc_is_spi_pin0_out>;
		pinctrl-2 = <&fimc_is_spi_pin0_fn>;

		num-cs = <1>;

		fimc_is_spi_0@0 {
			compatible = "samsung,fimc_is_spi0";
			spi-max-frequency = <50000000>;
			reg = <0x0>;
			pinctrl-names = "ssn_out", "ssn_fn", "ssn_inpd", "ssn_inpu";
			pinctrl-0 = <&fimc_is_spi_ssn0_out>;
			pinctrl-1 = <&fimc_is_spi_ssn0_fn>;
			pinctrl-2 = <&fimc_is_spi_ssn0_inpd>;
			pinctrl-3 = <&fimc_is_spi_ssn0_inpu>;

			use_spi_pinctrl; /* define if camera use spi */

			controller-data {
				cs-gpio = <&gpc3 1 0>;
				samsung,spi-feedback-delay = <1>;
			};
		};
	};

	spi_9: spi@143A0000 {
		#address-cells = <1>;
		#size-cells = <0>;
		pinctrl-names = "default", "spi_out", "spi_fn";
		pinctrl-0 = <&fimc_is_spi_pin1_out>;
		pinctrl-1 = <&fimc_is_spi_pin1_out>;
		pinctrl-2 = <&fimc_is_spi_pin1_fn>;

		num-cs = <1>;

		fimc_is_spi_0@0 {
			compatible = "samsung,fimc_is_spi1";
			spi-max-frequency = <50000000>;
			reg = <0x0>;
			pinctrl-names = "ssn_out", "ssn_fn";
			pinctrl-0 = <&fimc_is_comp_int_out &fimc_is_spi_ssn1_out>;
			pinctrl-1 = <&fimc_is_comp_int_fn &fimc_is_spi_ssn1_fn>;

			use_spi_pinctrl; /* define if camera use spi */

			controller-data {
				cs-gpio = <&gpc3 5 0>;
				samsung,spi-feedback-delay = <0>;
			};
		};
	};

	i2c@3d{
		compatible = "i2c-gpio";
		pinctrl-names = "default","i2c_host","i2c_fw";
		pinctrl-0 = <&fimc_is_i2c0_off>;
		pinctrl-1 = <&fimc_is_i2c0_host>;
		pinctrl-2 = <&fimc_is_i2c0_fw>;
		gpios = <&gpc2 0 0 /* sda */
			&gpc2 1 0 /* scl */
			>;
		i2c-gpio,delay-us = <2>;
		#address-cells = <1>;
		#size-cells = <0>;
		status = "okay";

		fimc-is-vision@3d {
			compatible = "samsung,fimc_is_i2c0";
			reg = <0x3d>;
		};
	};

	/* reprocessor driver */
	fimc_is_preprocessor: fimc_is_preprocessor@14020000 {
		compatible = "samsung,exynos5-fimc-is-preprocessor";
		samsung,power-domain = <&pd_cam1>;
		clock-names = "isp_sensor1",
			/* CAM1 600 */
			"gate_i2c0_isp",
			"gate_i2c1_isp",
			"gate_i2c2_isp",
			"gate_i2c3_isp",
			"gate_wdt_isp",
			"gate_mcuctl_isp",
			"gate_uart_isp",
			"gate_pdma_isp",
			"gate_pwm_isp",
			"gate_spi0_isp",
			"gate_spi1_isp",
			"isp_spi0",
			"isp_spi1",
			"isp_uart",
			"gate_sclk_pwm_isp",
			"gate_sclk_uart_isp",
			"cam1_peri";
		clocks =
			/* SENSOR1 MCLK */
			<&clock 501>,
			<&clock 605>,
			<&clock 606>,
			<&clock 607>,
			<&clock 608>,
			<&clock 609>,
			<&clock 610>,
			<&clock 611>,
			<&clock 612>,
			<&clock 613>,
			<&clock 614>,
			<&clock 615>,
			<&clock 616>,
			<&clock 617>,
			<&clock 618>,
			<&clock 619>,
			<&clock 620>,
			<&clock 625>;
		scenario = <0>;	/* Normal, Vision, OIS etc */
		id = <0>; /* bns_id */
		mclk_ch = <1>;
		status = "okay";
	};

	fimc_is_sensor_2l1: fimc-is_sensor_2l1@5A {
		compatible = "samsung,exynos5-fimc-is-sensor-2l1";

		pinctrl-names = "pin0", "pin1", "pin2";
		pinctrl-0 = <>;
		pinctrl-1 = <&fimc_is_flash_is &fimc_is_mclk0_out &fimc_is_mclk1_out>;
		pinctrl-2 = <&fimc_is_flash_is &fimc_is_mclk0_fn &fimc_is_mclk1_fn>;

		position = <0>;	/* Rear:0. Front:1 */
		id = <0>; /* bns_id */
		mclk_ch = <0>;
		sensor_i2c_ch = <0>; /* I2C 0 */
		sensor_i2c_addr = <0x5A>;

		gpio_mclk = <&gpk0 0 0x1>;
		gpio_reset = <&gpc1 0 0x1>; /* sensor reset */
		gpio_prep_reset = <&gpc1 2 0x1>; /* preprocessor reset */
		status = "okay";

		af {
			product_name = <12>; /* ak7371 */
			i2c_addr = <0x18>;
			i2c_ch = <2>; /* I2C 2 */
		};

		flash {
			product_name = <3>; /* S2MPB02 */
			flash_first_gpio = <2>;
			flash_second_gpio = <3>;
		};

		preprocessor {
			product_name = <3>; /* 73C3 */
			spi_channel = <1>;
			i2c_addr = <0x7A>;
			i2c_ch = <0>; /* I2C 0*/
			dma_ch = <2>; /* DMA VC2*/
		};

		ois {
			product_name = <1>; /* IDG2030 */
			i2c_addr = <0x48>;
			i2c_ch = <2>; /* I2C 2 */
		};
	};

	fimc_is_sensor_imx260: fimc-is_sensor_imx260@34 {
		compatible = "samsung,exynos5-fimc-is-sensor-imx260";

		pinctrl-names = "pin0", "pin1", "pin2";
		pinctrl-0 = <>;
		pinctrl-1 = <&fimc_is_flash_is &fimc_is_mclk0_out &fimc_is_mclk1_out>;
		pinctrl-2 = <&fimc_is_flash_is &fimc_is_mclk0_fn &fimc_is_mclk1_fn>;

		position = <0>;	/* Rear:0. Front:1 */
		id = <0>; /* bns_id */
		mclk_ch = <0>;
		sensor_i2c_ch = <0>; /* I2C 0 */
		sensor_i2c_addr = <0x34>;

		gpio_mclk = <&gpk0 0 0x1>;
		gpio_reset = <&gpc1 0 0x1>; /* sensor reset */
		gpio_prep_reset = <&gpc1 2 0x1>; /* preprocessor reset */
		status = "okay";

		af {
			product_name = <12>; /* ak7371 */
			i2c_addr = <0x18>;
			i2c_ch = <2>; /* I2C 2 */
		};

		flash {
			product_name = <3>; /* S2MPB02 */
			flash_first_gpio = <2>;
			flash_second_gpio = <3>;
		};

		preprocessor {
			product_name = <3>; /* 73C3 */
			spi_channel = <1>;
			i2c_addr = <0x7A>;
			i2c_ch = <0>; /* I2C 0*/
			dma_ch = <2>; /* DMA VC2*/
		};

		ois {
			product_name = <1>; /* IDG2030 */
			i2c_addr = <0x48>;
			i2c_ch = <2>; /* I2C 2 */
		};
	};

	hsi2c@136A0000 {
		status = "okay";
		clock-frequency = <400000>;
		pinctrl-names = "default","on_i2c","off_i2c";
		pinctrl-0 = <&fimc_is_hsi2c_off &fimc_is_i2c2_off>;
		pinctrl-1 = <&fimc_is_ois_hsi2c_on &fimc_is_i2c2_off>;
		pinctrl-2 = <&fimc_is_hsi2c_off &fimc_is_i2c2_fw>;
		ois@24{
			compatible = "rumba,ois";
			reg = <0x24>;
		};

		af@0c{
			compatible = "samsung,af";
			reg = <0x0c>;
		};

		front_eeprom@51 {
			compatible = "samsung,front-eeprom-i2c";
			reg = <0x51>;
		};
	};

	fimc_is_sensor_4e6_c2: fimc-is_sensor_4e6_c2@6A {
		compatible = "samsung,exynos5-fimc-is-sensor-4e6-c2";

		pinctrl-names = "pin0", "pin1", "pin2";
		pinctrl-0 = <>;
		pinctrl-1 = <&fimc_is_mclk1_out &fimc_is_mclk2_out &fimc_is_i2c1_out>;
		pinctrl-2 = <&fimc_is_mclk1_fn &fimc_is_mclk2_fn &fimc_is_i2c1>;

		position = <1>;	/* Rear:0. Front:1 */
		id = <0>; /* sensor node id */
		mclk_ch = <2>;
		sensor_i2c_ch = <1>;
		sensor_i2c_addr = <0x6A>;

		gpio_mclk = <&gpk0 2 0x1>;
		gpio_reset = <&gpc0 4 0x1>;
		gpio_standby = <&gpc1 1 0x1>;
		gpio_prep_reset = <&gpc1 2 0x1>; /* preprocesosr reset */
		status = "okay";

		preprocessor {
			product_name = <3>; /* 73C3 */
			spi_channel = <1>;
			i2c_addr = <0x7A>;
			i2c_ch = <0>; /* I2C 0*/
			dma_ch = <2>; /* DMA VC2*/
		};
	};

	fimc_is_sensor_4e6: fimc-is_sensor_4e6@6A {
		compatible = "samsung,exynos5-fimc-is-sensor-4e6";

		pinctrl-names = "pin0", "pin1", "pin2";
		pinctrl-0 = <>;
		pinctrl-1 = <&fimc_is_mclk2_out &fimc_is_i2c1>;
		pinctrl-2 = <&fimc_is_mclk2_fn &fimc_is_i2c1>;

		position = <1>;	/* Rear:0. Front:1 */
		id = <1>; /* sensor node id */
		mclk_ch = <2>;
		sensor_i2c_ch = <1>;
		sensor_i2c_addr = <0x6A>;

		gpio_mclk = <&gpk0 2 0x1>;
		gpio_reset = <&gpc0 4 0x1>;
		gpio_standby = <&gpc1 1 0x1>;
		status = "okay";
	};

	fimc_is_sensor_4e6_c2_stdby: fimc-is_sensor_4e6_c2_stdby@6A {
		compatible = "samsung,exynos5-fimc-is-sensor-4e6-c2";

		pinctrl-names = "pin0", "pin1", "pin2";
		pinctrl-0 = <>;
		pinctrl-1 = <&fimc_is_mclk1_out &fimc_is_mclk2_out &fimc_is_i2c1_out>;
		pinctrl-2 = <&fimc_is_mclk1_fn &fimc_is_mclk2_fn &fimc_is_i2c1>;

		position = <1>;	/* Rear:0. Front:1 */
		id = <5>; /* sensor node id */
		mclk_ch = <2>;
		sensor_i2c_ch = <1>;
		sensor_i2c_addr = <0x6A>;

		gpio_mclk = <&gpk0 2 0x1>;
		gpio_reset = <&gpc0 4 0x1>;
		gpio_standby = <&gpc1 1 0x1>;
		gpio_prep_reset = <&gpc1 2 0x1>; /* preprocesosr reset */
		status = "okay";

		preprocessor {
			product_name = <3>; /* 73C3 */
			spi_channel = <1>;
			i2c_addr = <0x7A>;
			i2c_ch = <0>; /* I2C 0*/
			dma_ch = <2>; /* DMA VC2*/
		};
	};

	fimc_is_sensor_imx260_stdby: fimc-is_sensor_imx260_stdby@34 {
		compatible = "samsung,exynos5-fimc-is-sensor-imx260";

		pinctrl-names = "pin0", "pin1", "pin2";
		pinctrl-0 = <>;
		pinctrl-1 = <&fimc_is_flash_is &fimc_is_mclk0_out &fimc_is_mclk1_out>;
		pinctrl-2 = <&fimc_is_flash_is &fimc_is_mclk0_fn &fimc_is_mclk1_fn>;

		position = <0>;	/* Rear:0. Front:1 */
		id = <4>; /* bns_id */
		mclk_ch = <0>;
		sensor_i2c_ch = <0>; /* I2C 0 */
		sensor_i2c_addr = <0x34>;

		gpio_mclk = <&gpk0 0 0x1>;
		gpio_reset = <&gpc1 0 0x1>; /* sensor reset */
		gpio_prep_reset = <&gpc1 2 0x1>; /* preprocessor reset */
		status = "okay";

		af {
			product_name = <12>; /* ak7371 */
			i2c_addr = <0x18>;
			i2c_ch = <2>; /* I2C 2 */
		};

		flash {
			product_name = <3>; /* S2MPB02 */
			flash_first_gpio = <2>;
			flash_second_gpio = <3>;
		};

		preprocessor {
			product_name = <3>; /* 73C3 */
			spi_channel = <1>;
			i2c_addr = <0x7A>;
			i2c_ch = <0>; /* I2C 0*/
			dma_ch = <2>; /* DMA VC2*/
		};

		ois {
			product_name = <1>; /* IDG2030 */
			i2c_addr = <0x48>;
			i2c_ch = <2>; /* I2C 2 */
		};
	};

	fimc_is_sensor_2l1_stdby: fimc-is_sensor_2l1_stdby@5A {
		compatible = "samsung,exynos5-fimc-is-sensor-2l1";

		pinctrl-names = "pin0", "pin1", "pin2";
		pinctrl-0 = <>;
		pinctrl-1 = <&fimc_is_flash_is &fimc_is_mclk0_out &fimc_is_mclk1_out>;
		pinctrl-2 = <&fimc_is_flash_is &fimc_is_mclk0_fn &fimc_is_mclk1_fn>;

		position = <0>;	/* Rear:0. Front:1 */
		id = <4>; /* bns_id */
		mclk_ch = <0>;
		sensor_i2c_ch = <0>; /* I2C 0 */
		sensor_i2c_addr = <0x5A>;

		gpio_mclk = <&gpk0 0 0x1>;
		gpio_reset = <&gpc1 0 0x1>; /* sensor reset */
		gpio_prep_reset = <&gpc1 2 0x1>; /* preprocessor reset */
		status = "okay";

		af {
			product_name = <12>; /* ak7371 */
			i2c_addr = <0x18>;
			i2c_ch = <2>; /* I2C 2 */
		};

		flash {
			product_name = <3>; /* S2MPB02 */
			flash_first_gpio = <2>;
			flash_second_gpio = <3>;
		};

		preprocessor {
			product_name = <3>; /* 73C3 */
			spi_channel = <1>;
			i2c_addr = <0x7A>;
			i2c_ch = <0>; /* I2C 0*/
			dma_ch = <2>; /* DMA VC2*/
		};

		ois {
			product_name = <1>; /* IDG2030 */
			i2c_addr = <0x48>;
			i2c_ch = <2>; /* I2C 2 */
		};
	};

	#define SENSOR_SCENARIO_NORMAL		0
	#define SENSOR_SCENARIO_VISION		1
	#define SENSOR_SCENARIO_EXTERNAL	2
	#define SENSOR_SCENARIO_OIS_FACTORY	3
	#define SENSOR_SCENARIO_VIRTUAL		9
	#define FLITE_ID_NOTHING 100

	fimc_is_sensor0: fimc_is_sensor@14000000 {
		scenario = <SENSOR_SCENARIO_NORMAL>;	/* Normal, Vision, OIS etc */
		id = <0>;
		csi_ch = <0>;
		flite_ch = <0>;
		is_bns = <1>;
		status = "okay";
	};

	fimc_is_sensor1: fimc_is_sensor@14100000 {
		scenario = <SENSOR_SCENARIO_NORMAL>;	/* Normal, Vision, OIS etc */
		id = <1>;
		csi_ch = <2>;
		flite_ch = <0>;
		is_bns = <1>;
		status = "okay";
	};

	fimc_is_sensor2: fimc_is_sensor@14010000 {
		scenario = <SENSOR_SCENARIO_NORMAL>;	/* Normal, Vision, OIS etc */
		id = <2>;
		csi_ch = <1>;
		flite_ch = <FLITE_ID_NOTHING>;
		is_bns = <0>;
		status = "okay";
	};

	fimc_is_sensor3: fimc_is_sensor@14020000 {
		scenario = <SENSOR_SCENARIO_NORMAL>;	/* Normal, Vision, OIS etc */
		id = <3>;
		csi_ch = <3>;
		flite_ch = <FLITE_ID_NOTHING>;
		is_bns = <0>;
		status = "okay";
	};

	fimc_is_sensor4: fimc_is_sensor_stdby@14000000 {
		scenario = <SENSOR_SCENARIO_NORMAL>;	/* Normal, Vision, OIS etc */
		id = <4>;
		csi_ch = <0>;
		flite_ch = <0>;
		is_bns = <1>;
		status = "okay";
	};

	fimc_is_sensor5: fimc_is_sensor_stdby_front@14000000 {
		scenario = <SENSOR_SCENARIO_NORMAL>;	/* Normal, Vision, OIS etc */
		id = <5>;
		csi_ch = <0>;
		flite_ch = <0>;
		is_bns = <1>;
		status = "okay";
	};

	fimc_is@14370000 {
		pinctrl-names = "default", "release";
		pinctrl-0 = <&fimc_is_flash_is &fimc_is_mclk0_out &fimc_is_mclk1_out &fimc_is_mclk2_out>;
		pinctrl-1 = <>;

		vender {
			rear_sensor_id = <109>; /* imx240:104,  imx260:109, 2L1:29*/
			front_sensor_id = <21>;
			use_module_check;
			use_ois_hsi2c;
			use_ois;
			check_sensor_vendor;

			total_camera_num = <2>;
			camera_info0 {				// 0 : rear
				isp = <0>;			/* 0 : INT , 1 : EXT , 2 : SOC */
				cal_memory = <1>;		/* 0 : N , 1 : FROM , 2 : EEPROM , 3 : OTP  */
				read_version = <0>;		/* 0 : SYSFS , 1 : CAMON */
				core_voltage = <1>;		/* 0 : N , 1 : Y  */
				upgrade = <0>;		/* 0 : N , 1 : SYSFS , 2 : CAMON */
				fw_write = <0>;		/* 0 : N,  1 : OS, 2 : SD, 3 : ALL */
				fw_dump = <0>;		/* 0 : N , 1 : Y  */
				companion = <1>;		/* 0 : N , 1 : Y  */
				ois = <1>;			/* 0 : N , 1 : Y  */
			};
			camera_info1 {				// 1 : front
				isp = <0>;			/* 0 : INT , 1 : EXT , 2 : SOC */
				cal_memory = <2>;		/* 0 : N , 1 : FROM , 2 : EEPROM , 3 : OTP  */
				read_version = <0>;		/* 0 : SYSFS , 1 : CAMON */
				core_voltage = <0>;		/* 0 : N , 1 : Y  */
				upgrade = <0>;		/* 0 : N , 1 : SYSFS , 2 : CAMON */
				fw_write = <0>;		/* 0 : N,  1 : OS, 2 : SD, 3 : ALL */
				fw_dump = <0>;		/* 0 : N , 1 : Y  */
				companion = <1>;		/* 0 : N , 1 : Y  */
				ois = <0>;			/* 0 : N , 1 : Y  */
			};
		};

		fimc_is_dvfs {
			#define DVFS_INT_L0 690000
			#define DVFS_INT_L1 680000
			#define DVFS_INT_L2 670000
			#define DVFS_INT_L3 660000
			#define DVFS_INT_L4 650000
			#define DVFS_INT_L5 640000
			#define DVFS_INT_L6 630000
			#define DVFS_INT_L7 620000
			#define DVFS_INT_L8 610000
			#define DVFS_INT_L9 600000
			#define DVFS_INT_L10 468000
			#define DVFS_INT_L11 400000
			#define DVFS_INT_L12 336000
			#define DVFS_INT_L13 255000
			#define DVFS_INT_L14 200000
			#define DVFS_INT_L15 168000
			#define DVFS_INT_L16 127000

			#define DVFS_CAM_L0 690000
			#define DVFS_CAM_L1 680000
			#define DVFS_CAM_L2 670000
			#define DVFS_CAM_L3 660000
			#define DVFS_CAM_L4 650000
			#define DVFS_CAM_L5 640000
			#define DVFS_CAM_L6 630000
			#define DVFS_CAM_L7 620000
			#define DVFS_CAM_L8 610000
			#define DVFS_CAM_L9 600000

			#define DVFS_MIF_L0 1794000
			#define DVFS_MIF_L1 1716000
			#define DVFS_MIF_L2 1539000
			#define DVFS_MIF_L3 1352000
			#define DVFS_MIF_L4 1144000
			#define DVFS_MIF_L5 1014000
			#define DVFS_MIF_L6 845000
			#define DVFS_MIF_L7 676000
			#define DVFS_MIF_L8 546000
			#define DVFS_MIF_L9 421000
			#define DVFS_MIF_L10 286000
			#define DVFS_MIF_L11 208000

			table0 {
				desc = "dvfs table v0.4 for 16M/5M";

				default_int = <DVFS_INT_L0>;
				default_cam = <DVFS_CAM_L0>;
				default_mif = <DVFS_MIF_L0>;
				default_i2c = <0>;
				default_hpg = <1>;

				front_preview_int = <DVFS_INT_L5>;
				front_preview_cam = <DVFS_CAM_L5>;
				front_preview_mif = <DVFS_MIF_L6>;
				front_preview_i2c = <0>;
				front_preview_hpg = <1>;

				front_capture_int = <DVFS_INT_L0>;
				front_capture_cam = <DVFS_CAM_L5>;
				front_capture_mif = <DVFS_MIF_L0>;
				front_capture_i2c = <0>;
				front_capture_hpg = <1>;

				front_video_int = <DVFS_INT_L5>;
				front_video_cam = <DVFS_CAM_L5>;
				front_video_mif = <DVFS_MIF_L6>;
				front_video_i2c = <0>;
				front_video_hpg = <1>;

				front_video_whd_int = <DVFS_INT_L5>;
				front_video_whd_cam = <DVFS_CAM_L5>;
				front_video_whd_mif = <DVFS_MIF_L6>;
				front_video_whd_i2c = <0>;
				front_video_whd_hpg = <1>;

				front_video_capture_int = <DVFS_INT_L0>;
				front_video_capture_cam = <DVFS_CAM_L5>;
				front_video_capture_mif = <DVFS_MIF_L0>;
				front_video_capture_i2c = <0>;
				front_video_capture_hpg = <1>;

				front_video_whd_capture_int = <DVFS_INT_L0>;
				front_video_whd_capture_cam = <DVFS_CAM_L5>;
				front_video_whd_capture_mif = <DVFS_MIF_L0>;
				front_video_whd_capture_i2c = <0>;
				front_video_whd_capture_hpg = <1>;

				front_no_preproc_int = <DVFS_INT_L5>;
				front_no_preproc_cam = <DVFS_CAM_L5>;
				front_no_preproc_mif = <DVFS_MIF_L6>;
				front_no_preproc_i2c = <0>;
				front_no_preproc_hpg = <1>;

				front_vt1_int = <DVFS_INT_L5>;
				front_vt1_cam = <DVFS_CAM_L5>;
				front_vt1_mif = <DVFS_MIF_L6>;
				front_vt1_i2c = <0>;
				front_vt1_hpg = <1>;

				front_vt2_int = <DVFS_INT_L5>;
				front_vt2_cam = <DVFS_CAM_L5>;
				front_vt2_mif = <DVFS_MIF_L6>;
				front_vt2_i2c = <0>;
				front_vt2_hpg = <1>;

				front_vt4_int = <DVFS_INT_L5>;
				front_vt4_cam = <DVFS_CAM_L5>;
				front_vt4_mif = <DVFS_MIF_L6>;
				front_vt4_i2c = <0>;
				front_vt4_hpg = <1>;

				rear_preview_fhd_int = <DVFS_INT_L4>;
				rear_preview_fhd_cam = <DVFS_CAM_L2>;
				rear_preview_fhd_mif = <DVFS_MIF_L6>;
				rear_preview_fhd_i2c = <0>;
				rear_preview_fhd_hpg = <1>;

				rear_preview_whd_int = <DVFS_INT_L3>;
				rear_preview_whd_cam = <DVFS_CAM_L2>;
				rear_preview_whd_mif = <DVFS_MIF_L5>;
				rear_preview_whd_i2c = <0>;
				rear_preview_whd_hpg = <1>;

				rear_preview_uhd_int = <DVFS_INT_L3>;
				rear_preview_uhd_cam = <DVFS_CAM_L2>;
				rear_preview_uhd_mif = <DVFS_MIF_L3>;
				rear_preview_uhd_i2c = <0>;
				rear_preview_uhd_hpg = <1>;

				rear_preview_uhd_60fps_int = <DVFS_INT_L1>;
				rear_preview_uhd_60fps_cam = <DVFS_CAM_L1>;
				rear_preview_uhd_60fps_mif = <DVFS_MIF_L0>;
				rear_preview_uhd_60fps_i2c = <0>;
				rear_preview_uhd_60fps_hpg = <1>;

				rear_capture_int = <DVFS_INT_L0>;
				rear_capture_cam = <DVFS_CAM_L2>;
				rear_capture_mif = <DVFS_MIF_L0>;
				rear_capture_i2c = <0>;
				rear_capture_hpg = <1>;

				rear_video_fhd_int = <DVFS_INT_L4>;
				rear_video_fhd_cam = <DVFS_CAM_L2>;
				rear_video_fhd_mif = <DVFS_MIF_L6>;
				rear_video_fhd_i2c = <0>;
				rear_video_fhd_hpg = <1>;

				rear_video_whd_int = <DVFS_INT_L3>;
				rear_video_whd_cam = <DVFS_CAM_L2>;
				rear_video_whd_mif = <DVFS_MIF_L5>;
				rear_video_whd_i2c = <0>;
				rear_video_whd_hpg = <1>;

				rear_video_uhd_int = <DVFS_INT_L3>;
				rear_video_uhd_cam = <DVFS_CAM_L2>;
				rear_video_uhd_mif = <DVFS_MIF_L3>;
				rear_video_uhd_i2c = <0>;
				rear_video_uhd_hpg = <1>;

				rear_video_uhd_60fps_int = <DVFS_INT_L1>;
				rear_video_uhd_60fps_cam = <DVFS_CAM_L1>;
				rear_video_uhd_60fps_mif = <DVFS_MIF_L0>;
				rear_video_uhd_60fps_i2c = <0>;
				rear_video_uhd_60fps_hpg = <1>;

				rear_video_fhd_capture_int = <DVFS_INT_L0>;
				rear_video_fhd_capture_cam = <DVFS_CAM_L2>;
				rear_video_fhd_capture_mif = <DVFS_MIF_L0>;
				rear_video_fhd_capture_i2c = <0>;
				rear_video_fhd_capture_hpg = <1>;

				rear_video_whd_capture_int = <DVFS_INT_L0>;
				rear_video_whd_capture_cam = <DVFS_CAM_L2>;
				rear_video_whd_capture_mif = <DVFS_MIF_L0>;
				rear_video_whd_capture_i2c = <0>;
				rear_video_whd_capture_hpg = <1>;

				rear_video_uhd_capture_int = <DVFS_INT_L0>;
				rear_video_uhd_capture_cam = <DVFS_CAM_L2>;
				rear_video_uhd_capture_mif = <DVFS_MIF_L0>;
				rear_video_uhd_capture_i2c = <0>;
				rear_video_uhd_capture_hpg = <1>;

				dual_preview_int = <DVFS_INT_L6>;
				dual_preview_cam = <DVFS_CAM_L2>;
				dual_preview_mif = <DVFS_MIF_L6>;
				dual_preview_i2c = <0>;
				dual_preview_hpg = <1>;

				dual_capture_int = <DVFS_INT_L0>;
				dual_capture_cam = <DVFS_CAM_L2>;
				dual_capture_mif = <DVFS_MIF_L0>;
				dual_capture_i2c = <0>;
				dual_capture_hpg = <1>;

				dual_video_int = <DVFS_INT_L6>;
				dual_video_cam = <DVFS_CAM_L2>;
				dual_video_mif = <DVFS_MIF_L6>;
				dual_video_i2c = <0>;
				dual_video_hpg = <1>;

				dual_video_capture_int = <DVFS_INT_L0>;
				dual_video_capture_cam = <DVFS_CAM_L2>;
				dual_video_capture_mif = <DVFS_MIF_L0>;
				dual_video_capture_i2c = <0>;
				dual_video_capture_hpg = <1>;

				preview_high_speed_fps_int = <DVFS_INT_L2>;
				preview_high_speed_fps_cam = <DVFS_CAM_L1>;
				preview_high_speed_fps_mif = <DVFS_MIF_L5>;
				preview_high_speed_fps_i2c = <0>;
				preview_high_speed_fps_hpg = <1>;

				video_high_speed_60fps_swvdis_int = <DVFS_INT_L4>;
				video_high_speed_60fps_swvdis_cam = <DVFS_CAM_L1>;
				video_high_speed_60fps_swvdis_mif = <DVFS_MIF_L4>;
				video_high_speed_60fps_swvdis_i2c = <0>;
				video_high_speed_60fps_swvdis_hpg = <1>;

				video_high_speed_60fps_int = <DVFS_INT_L4>;
				video_high_speed_60fps_cam = <DVFS_CAM_L1>;
				video_high_speed_60fps_mif = <DVFS_MIF_L5>;
				video_high_speed_60fps_i2c = <0>;
				video_high_speed_60fps_hpg = <1>;

				video_high_speed_120fps_int = <DVFS_INT_L2>;
				video_high_speed_120fps_cam = <DVFS_CAM_L1>;
				video_high_speed_120fps_mif = <DVFS_MIF_L5>;
				video_high_speed_120fps_i2c = <0>;
				video_high_speed_120fps_hpg = <1>;

				video_high_speed_240fps_int = <DVFS_INT_L1>;
				video_high_speed_240fps_cam = <DVFS_CAM_L1>;
				video_high_speed_240fps_mif = <DVFS_MIF_L2>;
				video_high_speed_240fps_i2c = <0>;
				video_high_speed_240fps_hpg = <1>;

				ext_rear_int = <DVFS_INT_L4>;
				ext_rear_cam = <DVFS_CAM_L0>;
				ext_rear_mif = <DVFS_MIF_L6>;
				ext_rear_i2c = <0>;
				ext_rear_hpg = <1>;

				ext_front_int = <DVFS_INT_L5>;
				ext_front_cam = <DVFS_CAM_L0>;
				ext_front_mif = <DVFS_MIF_L6>;
				ext_front_i2c = <0>;
				ext_front_hpg = <1>;

				max_int = <DVFS_INT_L0>;
				max_cam = <DVFS_CAM_L0>;
				max_mif = <DVFS_MIF_L0>;
				max_i2c = <0>;
				max_hpg = <1>;
			};

			table1 {
				desc = "DVFS table for HAL3";

				default_int = <DVFS_INT_L0>;
				default_cam = <DVFS_CAM_L0>;
				default_mif = <DVFS_MIF_L0>;
				default_i2c = <0>;
				default_hpg = <1>;

				front_preview_int = <DVFS_INT_L4>;
				front_preview_cam = <DVFS_CAM_L5>;
				front_preview_mif = <DVFS_MIF_L6>;
				front_preview_i2c = <0>;
				front_preview_hpg = <1>;

				front_capture_int = <DVFS_INT_L0>;
				front_capture_cam = <DVFS_CAM_L5>;
				front_capture_mif = <DVFS_MIF_L0>;
				front_capture_i2c = <0>;
				front_capture_hpg = <1>;

				front_video_int = <DVFS_INT_L4>;
				front_video_cam = <DVFS_CAM_L5>;
				front_video_mif = <DVFS_MIF_L6>;
				front_video_i2c = <0>;
				front_video_hpg = <1>;

				front_video_whd_int = <DVFS_INT_L4>;
				front_video_whd_cam = <DVFS_CAM_L5>;
				front_video_whd_mif = <DVFS_MIF_L6>;
				front_video_whd_i2c = <0>;
				front_video_whd_hpg = <1>;

				front_video_capture_int = <DVFS_INT_L0>;
				front_video_capture_cam = <DVFS_CAM_L5>;
				front_video_capture_mif = <DVFS_MIF_L0>;
				front_video_capture_i2c = <0>;
				front_video_capture_hpg = <1>;

				front_video_whd_capture_int = <DVFS_INT_L0>;
				front_video_whd_capture_cam = <DVFS_CAM_L5>;
				front_video_whd_capture_mif = <DVFS_MIF_L0>;
				front_video_whd_capture_i2c = <0>;
				front_video_whd_capture_hpg = <1>;

				front_no_preproc_int = <DVFS_INT_L5>;
				front_no_preproc_cam = <DVFS_CAM_L5>;
				front_no_preproc_mif = <DVFS_MIF_L6>;
				front_no_preproc_i2c = <0>;
				front_no_preproc_hpg = <1>;

				front_vt1_int = <DVFS_INT_L4>;
				front_vt1_cam = <DVFS_CAM_L5>;
				front_vt1_mif = <DVFS_MIF_L6>;
				front_vt1_i2c = <0>;
				front_vt1_hpg = <1>;

				front_vt2_int = <DVFS_INT_L4>;
				front_vt2_cam = <DVFS_CAM_L5>;
				front_vt2_mif = <DVFS_MIF_L6>;
				front_vt2_i2c = <0>;
				front_vt2_hpg = <1>;

				front_vt4_int = <DVFS_INT_L4>;
				front_vt4_cam = <DVFS_CAM_L5>;
				front_vt4_mif = <DVFS_MIF_L6>;
				front_vt4_i2c = <0>;
				front_vt4_hpg = <1>;

				rear_preview_fhd_int = <DVFS_INT_L2>;
				rear_preview_fhd_cam = <DVFS_CAM_L2>;
				rear_preview_fhd_mif = <DVFS_MIF_L2>;
				rear_preview_fhd_i2c = <0>;
				rear_preview_fhd_hpg = <1>;

				rear_preview_whd_int = <DVFS_INT_L2>;
				rear_preview_whd_cam = <DVFS_CAM_L2>;
				rear_preview_whd_mif = <DVFS_MIF_L2>;
				rear_preview_whd_i2c = <0>;
				rear_preview_whd_hpg = <1>;

				rear_preview_uhd_int = <DVFS_INT_L2>;
				rear_preview_uhd_cam = <DVFS_CAM_L2>;
				rear_preview_uhd_mif = <DVFS_MIF_L2>;
				rear_preview_uhd_i2c = <0>;
				rear_preview_uhd_hpg = <1>;

				rear_preview_uhd_60fps_int = <DVFS_INT_L1>;
				rear_preview_uhd_60fps_cam = <DVFS_CAM_L1>;
				rear_preview_uhd_60fps_mif = <DVFS_MIF_L0>;
				rear_preview_uhd_60fps_i2c = <0>;
				rear_preview_uhd_60fps_hpg = <1>;

				rear_capture_int = <DVFS_INT_L2>;
				rear_capture_cam = <DVFS_CAM_L2>;
				rear_capture_mif = <DVFS_MIF_L0>;
				rear_capture_i2c = <0>;
				rear_capture_hpg = <1>;

				rear_video_fhd_int = <DVFS_INT_L2>;
				rear_video_fhd_cam = <DVFS_CAM_L2>;
				rear_video_fhd_mif = <DVFS_MIF_L2>;
				rear_video_fhd_i2c = <0>;
				rear_video_fhd_hpg = <1>;

				rear_video_whd_int = <DVFS_INT_L2>;
				rear_video_whd_cam = <DVFS_CAM_L2>;
				rear_video_whd_mif = <DVFS_MIF_L5>;
				rear_video_whd_i2c = <0>;
				rear_video_whd_hpg = <1>;

				rear_video_uhd_int = <DVFS_INT_L2>;
				rear_video_uhd_cam = <DVFS_CAM_L2>;
				rear_video_uhd_mif = <DVFS_MIF_L3>;
				rear_video_uhd_i2c = <0>;
				rear_video_uhd_hpg = <1>;

				rear_video_uhd_60fps_int = <DVFS_INT_L1>;
				rear_video_uhd_60fps_cam = <DVFS_CAM_L1>;
				rear_video_uhd_60fps_mif = <DVFS_MIF_L0>;
				rear_video_uhd_60fps_i2c = <0>;
				rear_video_uhd_60fps_hpg = <1>;

				rear_video_fhd_capture_int = <DVFS_INT_L2>;
				rear_video_fhd_capture_cam = <DVFS_CAM_L2>;
				rear_video_fhd_capture_mif = <DVFS_MIF_L0>;
				rear_video_fhd_capture_i2c = <0>;
				rear_video_fhd_capture_hpg = <1>;

				rear_video_whd_capture_int = <DVFS_INT_L2>;
				rear_video_whd_capture_cam = <DVFS_CAM_L2>;
				rear_video_whd_capture_mif = <DVFS_MIF_L0>;
				rear_video_whd_capture_i2c = <0>;
				rear_video_whd_capture_hpg = <1>;

				rear_video_uhd_capture_int = <DVFS_INT_L2>;
				rear_video_uhd_capture_cam = <DVFS_CAM_L2>;
				rear_video_uhd_capture_mif = <DVFS_MIF_L0>;
				rear_video_uhd_capture_i2c = <0>;
				rear_video_uhd_capture_hpg = <1>;

				dual_preview_int = <DVFS_INT_L0>;
				dual_preview_cam = <DVFS_CAM_L2>;
				dual_preview_mif = <DVFS_MIF_L3>;
				dual_preview_i2c = <0>;
				dual_preview_hpg = <1>;

				dual_capture_int = <DVFS_INT_L0>;
				dual_capture_cam = <DVFS_CAM_L2>;
				dual_capture_mif = <DVFS_MIF_L0>;
				dual_capture_i2c = <0>;
				dual_capture_hpg = <1>;

				dual_video_int = <DVFS_INT_L0>;
				dual_video_cam = <DVFS_CAM_L2>;
				dual_video_mif = <DVFS_MIF_L3>;
				dual_video_i2c = <0>;
				dual_video_hpg = <1>;

				dual_video_capture_int = <DVFS_INT_L0>;
				dual_video_capture_cam = <DVFS_CAM_L2>;
				dual_video_capture_mif = <DVFS_MIF_L0>;
				dual_video_capture_i2c = <0>;
				dual_video_capture_hpg = <1>;

				preview_high_speed_fps_int = <DVFS_INT_L2>;
				preview_high_speed_fps_cam = <DVFS_CAM_L1>;
				preview_high_speed_fps_mif = <DVFS_MIF_L5>;
				preview_high_speed_fps_i2c = <0>;
				preview_high_speed_fps_hpg = <1>;

				video_high_speed_60fps_swvdis_int = <DVFS_INT_L1>;
				video_high_speed_60fps_swvdis_cam = <DVFS_CAM_L1>;
				video_high_speed_60fps_swvdis_mif = <DVFS_MIF_L5>;
				video_high_speed_60fps_swvdis_i2c = <0>;
				video_high_speed_60fps_swvdis_hpg = <1>;

				video_high_speed_60fps_int = <DVFS_INT_L1>;
				video_high_speed_60fps_cam = <DVFS_CAM_L1>;
				video_high_speed_60fps_mif = <DVFS_MIF_L5>;
				video_high_speed_60fps_i2c = <0>;
				video_high_speed_60fps_hpg = <1>;

				video_high_speed_120fps_int = <DVFS_INT_L2>;
				video_high_speed_120fps_cam = <DVFS_CAM_L1>;
				video_high_speed_120fps_mif = <DVFS_MIF_L5>;
				video_high_speed_120fps_i2c = <0>;
				video_high_speed_120fps_hpg = <1>;

				video_high_speed_240fps_int = <DVFS_INT_L1>;
				video_high_speed_240fps_cam = <DVFS_CAM_L1>;
				video_high_speed_240fps_mif = <DVFS_MIF_L2>;
				video_high_speed_240fps_i2c = <0>;
				video_high_speed_240fps_hpg = <1>;

				ext_rear_int = <DVFS_INT_L4>;
				ext_rear_cam = <DVFS_CAM_L0>;
				ext_rear_mif = <DVFS_MIF_L6>;
				ext_rear_i2c = <0>;
				ext_rear_hpg = <1>;

				ext_front_int = <DVFS_INT_L5>;
				ext_front_cam = <DVFS_CAM_L0>;
				ext_front_mif = <DVFS_MIF_L6>;
				ext_front_i2c = <0>;
				ext_front_hpg = <1>;

				max_int = <DVFS_INT_L0>;
				max_cam = <DVFS_CAM_L0>;
				max_mif = <DVFS_MIF_L0>;
				max_i2c = <0>;
				max_hpg = <1>;
			};
		};
	};

	usb@15400000 {
		status = "okay";

		dwc3 {
			maximum-speed = "high-speed";
			dr_mode = "otg";
			suspend_clk_freq = <66000000>;
		};
	};

	phy@15500000 {
		use_additional_tuning;
	};

	usb_notifier {
		compatible = "samsung,usb-notifier";
		udc = <&udc>;
	};

	ipa_pdata {
		compatible = "samsung,exynos-ipa";

		control_temp = <100>;
		temp_threshold = <5>;
		enabled = <1>;
		tdp = <3500>;
		boost = <1>;
		ros_power = <500>;
		little_weight = <1024>;
		big_weight = <256>;
		gpu_weight = <256>;
		little_max_power = <1000>;
		big_max_power = <6552>;
		gpu_max_power = <3110>;
		hotplug_out_threshold = <10>;
		hotplug_in_threshold = <0>;
		enable_ctlr = <1>;
		ctlr.mult = <2>;
		ctlr.k_i = <1>;
		ctlr.k_d = <0>;
		ctlr.feed_forward = <1>;
		ctlr.integral_reset_value = <0>;
		ctlr.integral_cutoff = <0>;
		ctlr.integral_reset_threshold = <10>;
	};

	pinctrl@10E60000 {
		nfc_n5_en: nfc-n5-en {
			samsung,pins = "gpi2-7";
			samsung,pin-function = <1>;
			samsung,pin-pud = <0>;
			samsung,pin-val = <1>;
		};
	};

	pinctrl@14CC0000 {
		nfc_n5_firm: nfc-n5-firm {
			samsung,pins = "gpe7-0";
			samsung,pin-function = <1>;
			samsung,pin-pud = <1>;
			samsung,pin-val = <1>;
		};
	};

	hsi2c@13670000 {
		status = "okay";
		sec-nfc@27 {
			compatible = "sec-nfc";
			reg = <0x27>;

			interrupts = <2 0 0>;
			interrupt-parent = <&gpa1>;

			sec-nfc,ven-gpio = <&gpi2 7 0>;
			sec-nfc,irq-gpio = <&gpa1 2 0>;
			sec-nfc,firm-gpio = <&gpe7 0 0>;
			sec-nfc,clk_req-gpio = <&gpa2 7 0xf>;
			sec-nfc,clk_use = <2>;
			sec-nfc,nfc_pvdd = "VDD_NFC_1P8";
			pinctrl-names = "default";
			pinctrl-0 = <&nfc_n5_en &nfc_n5_firm>;

			clocks = <&clock 1000>;
			clock-names = "oscclk_nfc";
			sec-nfc,nfc_ap_clk;

			sec-nfc,ldo_control;
		};

		adpd143@64 {
			compatible = "adpd143";
			reg = <0x64>;
			interrupt-parent = <&gpa1>;
			interrupts = <7 0 0>;
			pinctrl-names = "default", "sleep", "idle";
			pinctrl-0 = <&hrm_irq>;
			pinctrl-1 = <&hrm_irqsleep>;
			pinctrl-2 = <&hrm_irqidle>;
			adpd143,irq_gpio = <&gpa1 7 0>;
			adpd143,vdd_1p8 = "HRM_1.8V_AP";
			adpd143,led_3p3 = "HRM_3.3V_AP";
			#adpd143,i2c_1p8= "VDD_NFC_1P8";
			adpd143,dual-hrm = <0>;
		};

		max86900@51 {
			compatible = "max86900";
			reg = <0x51>;
			interrupt-parent = <&gpa1>;
			interrupts = <7 0 0>;
			pinctrl-names = "default", "sleep", "idle";
			pinctrl-0 = <&hrm_irq>;
			pinctrl-1 = <&hrm_irqsleep>;
			pinctrl-2 = <&hrm_irqidle>;
			max86900,hrm_int-gpio = <&gpa1 7 0>;
			max86900,vdd_1p8 = "HRM_1.8V_AP";
			max86900,led_3p3 = "HRM_3.3V_AP";
		};
	};

	hsi2c@14E60000 {
		status = "okay";
		sx9310-i2c@28 {
			compatible = "sx9310-i2c";
			reg = <0x28>;
			status = "okay";
			pinctrl-names = "default";
			pinctrl-0 = <&grip_irq>;
			interrupt-parent = <&gpa2>;
			interrupts = <5 0 0>;
			sx9310-i2c,nirq-gpio = <&gpa2 5 0x00>;
			#sx9310-i2c,ldo-en = <&gpa1 7 0x00>;
		};
	};

	spi_3: spi@14d50000 {
		status = "okay";
		#address-cells = <1>;
		#size-cells = <0>;
		pinctrl-names = "default","ese-pwoff";
		pinctrl-0 = <&spi3_bus &spi3_cs_func>;
		pinctrl-1 = <&spi3_ese_pwoff>;
		samsung,ese-oberthur;

		ese_spi@0 {
			compatible = "ese_p3";
			reg = <0>;
			spi-max-frequency = <13000000>;

			gpio-controller;
			#gpio-cells = <2>;

			p3-cs-gpio = <&gpf2 1 0>;
			p3-vdd-1p8= "VDD_1.8V_ESE";

			controller-data {
				cs-gpio = <&gpf2 1 0>;
				samsung,spi-feedback-delay = <0>;
				samsung,spi-chip-select-mode = <0>;
			};
		};
	};

	sec_ese {
		compatible = "sec-coffee";
		status = "okay";

		coffee-vdd-1p8= "VDD_1.8V_ESE";
	};

	secgpio_dvs {
		compatible = "samsung,exynos8890-secgpio-dvs";
		status = "okay";
	};

 	sec_thermistor@0 {
		compatible = "samsung,sec-ap-thermistor";
		status = "okay";

		adc_array = <121 144 167 190 213 236 259 282 306 329
			352 366 379 393 406 420 436 452 468 484
			500 520 539 559 579 599 620 642 663 685
			706 731 756 780 805 832 859 886 914 943
			972 1010 1049 1079 1109 1142 1174 1210 1247 1284
			1321 1362 1404 1445 1487 1528 1572 1615 1659 1702
			1746 1789 1833 1876 1920 1963 2015 2066 2118 2169
			2221 2266 2312 2357 2403 2449 2494 2539 2584 2629
			2674 2719 2765 2811 2857 2903 2943 2983 3023 3063
			3104 3141 3178 3214 3250 3279 3308 3337 3367 3398
			3429 3455 3482 3508 3535 3562 3583 3605 3627 3649
			3671>;
		temp_array = <900 890 880 870 860 850 840 830 820 810
			800 790 780 770 760 750 740 730 720 710
			700 690 680 670 660 650 640 630 620 610
			600 590 580 570 560 550 540 530 520 510
			500 490 480 470 460 450 440 430 420 410
			400 390 380 370 360 350 340 330 320 310
			300 290 280 270 260 250 240 230 220 210
			200 190 180 170 160 150 140 130 120 110
			100 90 80 70 60 50 40 30 20 10
			0 (-10) (-20) (-30) (-40) (-50) (-60) (-70) (-80) (-90)
			(-100)(-110)(-120)(-130)(-140)(-150)(-160)(-170)(-180)(-190)
			(-200)>;

		io-channels = <&exynos_adc 0>;
		io-channel-names = "adc-ap-temp";
		io-channel-ranges;
	};

	sec_thermistor@2 {
		compatible = "samsung,sec-pa-thermistor";
		status = "okay";

		adc_array = <215 224 234 243 253 262 271 281 290 300
			309 322 335 348 361 374 389 404 418 433
			448 465 482 499 516 533 553 573 594 614
			634 658 682 705 729 753 780 807 833 860
			887 918 948 979 1009 1040 1076 1112 1147 1183
			1219 1257 1295 1332 1370 1408 1448 1489 1529 1570
			1610 1653 1696 1739 1782 1825 1869 1913 1957 2001
			2045 2090 2134 2179 2223 2268 2310 2352 2395 2437
			2479 2520 2561 2601 2642 2683 2720 2757 2793 2830
			2867 2903 2939 2975 3011 3047 3077 3106 3136 3165
			3195 3221 3247 3274 3300 3326 3348 3370 3392 3414
			3436>;
		temp_array = <900 890 880 870 860 850 840 830 820 810
			800 790 780 770 760 750 740 730 720 710
			700 690 680 670 660 650 640 630 620 610
			600 590 580 570 560 550 540 530 520 510
			500 490 480 470 460 450 440 430 420 410
			400 390 380 370 360 350 340 330 320 310
			300 290 280 270 260 250 240 230 220 210
			200 190 180 170 160 150 140 130 120 110
			100 90 80 70 60 50 40 30 20 10
			0 (-10) (-20) (-30) (-40) (-50) (-60) (-70) (-80) (-90)
			(-100)(-110)(-120)(-130)(-140)(-150)(-160)(-170)(-180)(-190)
			(-200)>;

		io-channels = <&exynos_adc 2>;
		io-channel-names = "adc-pa-temp";
		io-channel-ranges;
	};

	/* Modem_interface */
	mif_pdata {
		reg = <0x0 0x20C7800 0x800>;
		pinctrl-names = "default";

		/* To do: will be remove, for system revision */
		gpios = <&gpe4 4 0x0>,
		       <&gpe4 5 0x0>,
		       <&gpe4 6 0x0>,
		       <&gpe4 7 0x0>;

		mif,ap_clk_table = <
			/* khz */
			1898000
			1794000
			1690000
			1586000
			1482000
			1378000
			1274000
			1170000
			1066000
			962000
			858000
			754000
			650000
			546000
			442000
			>;

		mif,mif_clk_table = <
			/* khz L0-L9 */
			1794000
			1716000
			1539200
			1352000
			1144000
			1014000
			845000
			676000
			546000
			420875
			>;

		mif,int_clk_table = <
			/* khz */
			690000
			680000
			670000
			660000
			650000
			640000
			630000
			620000
			610000
			600000
			468000
			400000
			336000
			255000
			>;
	};

	bluetooth {
	compatible = "broadcom,bcm4359";
	gpios = <&gpj1 7 0	/*BT_EN*/
		&gpi2 3 0	/*BT_WAKE*/
		&gpa2 3 0xF	/*BT_HOST_WAKE*/ >;
	pinctrl-names = "default";
	pinctrl-0=<&bt_hostwake &bt_btwake &bt_en>;
	status = "okay";
	};

	mcu_ipc: mcu_ipc@10540000 {
		mcu,irq_affinity_mask = <3>;
	};

	argos {
		compatible = "samsung,argos";
		#address-cells = <1>;
		/*  The device number should be assigned for each device, e.g. "boot_device@1" and "boot_device@2".
		 * Duplicated number is not allowed. Please refer the below example. */

		/* Table Format should be
		 * <Throughput(Mbps) ARM_min ARM_max KFC_min KFC_max MIF INT Task IRQ HMP_boost>
		 * ARM_min : Big Core's minimum frequency lock. 0 means not set,
		 * ARM_max : Big Core's maximum frequency lock. 0 means not set,
		 * KFC_min : Little Core's minimum frequency lock. 0 means not set,
		 * KFC_max : Little Core's maximum frequency lock. 0 means not set,
		 * MIF : MIF frequency lock. 0 means not set,
		 * INT : INT frequency lock. 0 means not set,
		 * Task : 1 - Set task affinity lock.
		 *	0 - Not set or unlock,
		 *		Task affinity should be predefined driver's code.
		 * IRQ : 1 - Set irq affinity lock.
		 *       0 - Not set or unlock,
		 *		Task affinity should be predefined driver's code.
		 * HMP_boots : 1 - Increase hmp boosting count
		 *             0 - Decrease hmp boosting count
		 */
		boot_device@1 {
			net_boost,label="IPC";
			net_boost,node="rmnet0 rmnet1 rmnet2 rmnet3 rmnet4 rmnet5 rmnet6 rmnet7 umts_dm0";
			net_boost,table_size = <3>;
			net_boost,table= <
				100 0 0 1066000 0 845000 0 0 1 0
				200 0 0 1274000 0 1014000 0 0 1 0
				300 0 0 1586000 0 1794000 0 0 1 0
				>;
		};
		/* Example
		boot_device@2 {
			net_boost,label="EMMC";
			net_boost,node="";
			net_boost,sysnode="/sys/class/mmc_host/mmc0/trans_count";
			net_boost,table_size = <1>;
			net_boost,table= <64 0 0 1274000 0 845000 400000 0 0>;
		};
		*/
		boot_device@2 {
			net_boost,label="UFS";
			net_boost,node="";
			net_boost,sysnode="/sys/class/scsi_host/host0/transferred_cnt";
#if ANDROID_VERSION >= 70000
			net_boost,table_size = <2>;
			net_boost,table= <
				128 0 0 1274000 0 1144000 0 0 0 0
				800 0 0 1482000 0 1539000 0 0 0 0
				>;
#else
			net_boost,table_size = <1>;
			net_boost,table= <
				128 0 0 1274000 0 1144000 0 0 0 0
				>;
#endif
		};
		boot_device@3 {
			net_boost,label="P2P";
			net_boost,node="p2p-wlan0-0";
			net_boost,table_size = <3>;
			net_boost,table= <
				30 1144000 0 1170000 0 0 0 0 0 0
				90 1872000 0 1586000 0 0 255000 0 0 0
				120 2080000 0 1586000 0 546000 255000 0 0 1
				>;
		};

		boot_device@4 {
			net_boost,label="CLAT";
			net_boost,node="clat clat4 v4-rmnet0 v4-rmnet1 v4-rmnet2 v4-rmnet3 v4-rmnet4 v4-rmnet5 v4-rmnet6 v4-rmnet7";
			net_boost,table_size = <4>;
			net_boost,table= <
				120 1456000 0 0 0 845000 0 0 0 0
				130 1560000 0 0 0 845000 0 0 0 0
				150 1664000 0 0 0 845000 0 0 0 0
				200 1664000 0 1586000 0 1794000 0 0 0 0
				>;
		};

		boot_device@5 {
			net_boost,label="QIPC";
			net_boost,node="rmnet_data0 rmnet_data1 rmnet_data2 rmnet_data3 rmnet_data4 rmnet_data5 rmnet_data6 rmnet_data7";
			net_boost,table_size = <2>;
			net_boost,table= <
				10 0 0 1066000 0 845000 0 0 1 0 /* 10Mbps little core 1.1G */
				100 0 0 1482000 0 845000 0 0 1 0 /* 100Mbps little core 1.5G */
				>;
		};

		boot_device@6 {
			net_boost,label="USB";
			net_boost,node="rndis0";
			net_boost,table_size = <1>;
			net_boost,table= < 0 0 0 0 0 0 0 0 1 0 >;
		};

		boot_device@7 {
			net_boost,label="WIFI";
			net_boost,node="wlan0";
			net_boost,table_size = <1>;
			net_boost,table= <
				150 0 0 0 0 0 0 0 0 0
				>;
		};
		boot_device@8 {
			net_boost,label="WIFI TX";
			net_boost,node="wlan0";
			net_boost,table_size = <4>;
			net_boost,table= <
				40 1664000 0 1586000 0 0 0 0 0 0
				80 1976000 0 1586000 0 0 0 0 0 0
				150 2184000 0 1586000 0 845000 400000 1 1 1
				250 2288000 0 1586000 0 845000 400000 1 1 1
				>;
		};
		boot_device@9 {
			net_boost,label="WIFI RX";
			net_boost,node="wlan0";
			net_boost,table_size = <4>;
			net_boost,table= <
				100 1144000 0 1066000 0 0 0 0 0 0
				150 1456000 0 1378000 0 0 0 0 0 0
				200 1664000 0 1586000 0 845000 400000 1 1 1
				300 2288000 0 1586000 0 845000 400000 1 1 1
				>;
		};
		boot_device@10 {
			net_boost,label="SWLAN";
			net_boost,node="swlan0";
			net_boost,table_size = <3>;
			net_boost,table= <
				20 1456000 0 1170000 0 0 0 0 0 0
				60 1664000 0 1586000 0 0 0 0 0 0
				180 2288000 0 1586000 0 845000 400000 1 1 1
				>;
		};
	};

	exynos_pm_dvs {
		compatible = "samsung,exynos-pm-dvs";
		vdd_mldo {
			regulator_name = "vdd_mldo";
			suspend_volt = <1837500>;
			init_volt = <2000000>;
			volt_range_step = <25000>;
		};

		vdd_lldo {
			regulator_name = "vdd_lldo";
			suspend_volt = <1237500>;
			init_volt = <1300000>;
			volt_range_step = <25000>;
		};
	};
};
